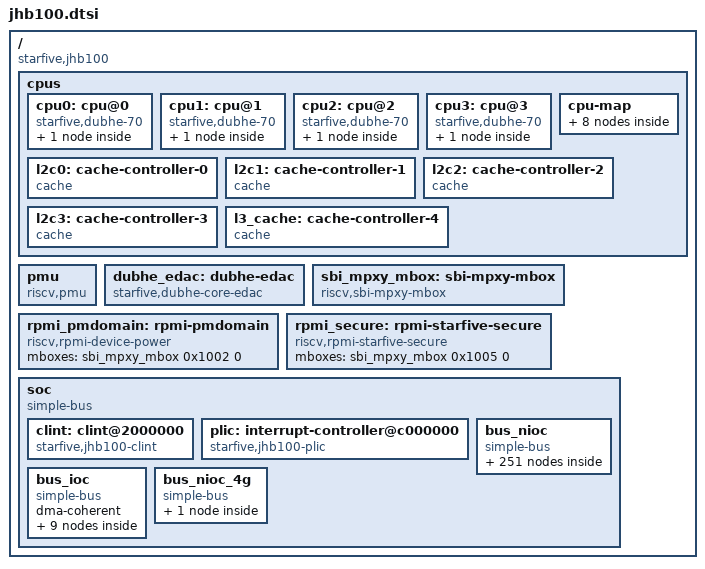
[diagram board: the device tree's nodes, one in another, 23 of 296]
// SPDX-License-Identifier: GPL-2.0 OR MIT
/*
 * Copyright (c) 2024 StarFive Technology Co., Ltd.
 */

/dts-v1/;
#include <dt-bindings/power/starfive,jhb100-power.h>
#include <dt-bindings/gpio/starfive,jhb100-gpio.h>
#include <dt-bindings/gpio/gpio.h>
#include "jhb100-crg.dtsi"
#include "jhb100-pinfunc.h"

/ {
	compatible = "starfive,jhb100";
	#address-cells = <2>;
	#size-cells = <2>;

	cpus {
		#address-cells = <1>;
		#size-cells = <0>;

		cpu0: cpu@0 {
			compatible = "starfive,dubhe-70", "riscv";
			riscv,isa = "rv64imafdcbh";
			riscv,isa-base = "rv64i";
			riscv,isa-extensions = "i", "m", "a", "f", "d", "c", "h", "zba", "zbb",
					       "zbc", "zbs", "zicbom", "zicbop", "zicboz", "zicntr",
					       "zicond", "zicsr", "zifencei", "zihintpause",
					       "zihpm", "svinval", "svnapot", "sscofpmf";
			riscv,cbom-block-size = <64>;
			riscv,cboz-block-size = <64>;
			d-cache-block-size = <64>;
			d-cache-sets = <512>;
			d-cache-size = <32768>;
			d-tlb-sets = <1>;
			d-tlb-size = <16>;
			device_type = "cpu";
			i-cache-block-size = <64>;
			i-cache-sets = <512>;
			i-cache-size = <32768>;
			i-tlb-sets = <1>;
			i-tlb-size = <24>;
			mmu-type = "riscv,sv48";
			next-level-cache = <&l2c0>;
			reg = <0x0>;
			tlb-split;

			cpu0_intc: interrupt-controller {
				compatible = "riscv,cpu-intc";
				interrupt-controller;
				#interrupt-cells = <1>;
			};
		};

		cpu1: cpu@1 {
			compatible = "starfive,dubhe-70", "riscv";
			riscv,isa = "rv64imafdcbh";
			riscv,isa-base = "rv64i";
			riscv,isa-extensions = "i", "m", "a", "f", "d", "c", "h", "zba", "zbb",
					       "zbc", "zbs", "zicbom", "zicbop", "zicboz", "zicntr",
					       "zicond", "zicsr", "zifencei", "zihintpause",
					       "zihpm", "svinval", "svnapot", "sscofpmf";
			riscv,cbom-block-size = <64>;
			riscv,cboz-block-size = <64>;
			d-cache-block-size = <64>;
			d-cache-sets = <512>;
			d-cache-size = <32768>;
			d-tlb-sets = <1>;
			d-tlb-size = <16>;
			device_type = "cpu";
			i-cache-block-size = <64>;
			i-cache-sets = <512>;
			i-cache-size = <32768>;
			i-tlb-sets = <1>;
			i-tlb-size = <24>;
			mmu-type = "riscv,sv48";
			next-level-cache = <&l2c1>;
			reg = <0x1>;
			tlb-split;

			cpu1_intc: interrupt-controller {
				compatible = "riscv,cpu-intc";
				interrupt-controller;
				#interrupt-cells = <1>;
			};
		};

		cpu2: cpu@2 {
			compatible = "starfive,dubhe-70", "riscv";
			riscv,isa = "rv64imafdcbh";
			riscv,isa-base = "rv64i";
			riscv,isa-extensions = "i", "m", "a", "f", "d", "c", "h", "zba", "zbb",
					       "zbc", "zbs", "zicbom", "zicbop", "zicboz", "zicntr",
					       "zicond", "zicsr", "zifencei", "zihintpause",
					       "zihpm", "svinval", "svnapot", "sscofpmf";
			riscv,cbom-block-size = <64>;
			riscv,cboz-block-size = <64>;
			d-cache-block-size = <64>;
			d-cache-sets = <512>;
			d-cache-size = <32768>;
			d-tlb-sets = <1>;
			d-tlb-size = <16>;
			device_type = "cpu";
			i-cache-block-size = <64>;
			i-cache-sets = <512>;
			i-cache-size = <32768>;
			i-tlb-sets = <1>;
			i-tlb-size = <24>;
			mmu-type = "riscv,sv48";
			next-level-cache = <&l2c2>;
			reg = <0x2>;
			tlb-split;

			cpu2_intc: interrupt-controller {
				compatible = "riscv,cpu-intc";
				interrupt-controller;
				#interrupt-cells = <1>;
			};
		};

		cpu3: cpu@3 {
			compatible = "starfive,dubhe-70", "riscv";
			riscv,isa = "rv64imafdcbh";
			riscv,isa-base = "rv64i";
			riscv,isa-extensions = "i", "m", "a", "f", "d", "c", "h", "zba", "zbb",
					       "zbc", "zbs", "zicbom", "zicbop", "zicboz", "zicntr",
					       "zicond", "zicsr", "zifencei", "zihintpause",
					       "zihpm", "svinval", "svnapot", "sscofpmf";
			riscv,cbom-block-size = <64>;
			riscv,cboz-block-size = <64>;
			d-cache-block-size = <64>;
			d-cache-sets = <512>;
			d-cache-size = <32768>;
			d-tlb-sets = <1>;
			d-tlb-size = <16>;
			device_type = "cpu";
			i-cache-block-size = <64>;
			i-cache-sets = <512>;
			i-cache-size = <32768>;
			i-tlb-sets = <1>;
			i-tlb-size = <24>;
			mmu-type = "riscv,sv48";
			next-level-cache = <&l2c3>;
			reg = <0x3>;
			tlb-split;

			cpu3_intc: interrupt-controller {
				compatible = "riscv,cpu-intc";
				interrupt-controller;
				#interrupt-cells = <1>;
			};
		};

		cpu-map {
			cluster0 {
				core0 {
					cpu = <&cpu0>;
				};
			};

			cluster1 {
				core0 {
					cpu = <&cpu1>;
				};
			};

			cluster2 {
				core0 {
					cpu = <&cpu2>;
				};
			};

			cluster3 {
				core0 {
					cpu = <&cpu3>;
				};
			};
		};

		l2c0: cache-controller-0 {
			compatible = "cache";
			cache-block-size = <64>;
			cache-level = <2>;
			cache-sets = <2048>;
			cache-size = <0x20000>;
			cache-unified;
			next-level-cache = <&l3_cache>;
		};

		l2c1: cache-controller-1 {
			compatible = "cache";
			cache-block-size = <64>;
			cache-level = <2>;
			cache-sets = <2048>;
			cache-size = <0x20000>;
			cache-unified;
			next-level-cache = <&l3_cache>;
		};

		l2c2: cache-controller-2 {
			compatible = "cache";
			cache-block-size = <64>;
			cache-level = <2>;
			cache-sets = <2048>;
			cache-size = <0x20000>;
			cache-unified;
			next-level-cache = <&l3_cache>;
		};

		l2c3: cache-controller-3 {
			compatible = "cache";
			cache-block-size = <64>;
			cache-level = <2>;
			cache-sets = <2048>;
			cache-size = <0x20000>;
			cache-unified;
			next-level-cache = <&l3_cache>;
		};

		l3_cache: cache-controller-4 {
			compatible = "cache";
			cache-block-size = <64>;
			cache-level = <3>;
			cache-sets = <1024>;
			cache-size = <0x20000>;
			cache-unified;
		};
	};

	pmu {
		compatible = "riscv,pmu";
		interrupts-extended = <&cpu0_intc 13>, <&cpu1_intc 13>,
				      <&cpu2_intc 13>, <&cpu3_intc 13>;

		riscv,event-to-mhpmevent = <0x00005 0x0000 0xA>,
					   <0x00006 0x0000 0xB>,
					   <0x00008 0x0000 0x10>,
					   <0x00009 0x0000 0xF>,
					   <0x10000 0x0000 0x19>,
					   <0x10001 0x0000 0x1A>,
					   <0x10002 0x0000 0x1B>,
					   <0x10003 0x0000 0x1C>,
					   <0x10008 0x0000 0x8>,
					   <0x10009 0x0000 0x9>,
					   <0x1000C 0x0000 0x9E>,
					   <0x1000D 0x0000 0x9F>,
					   <0x10010 0x0000 0x1D>,
					   <0x10011 0x0000 0x1E>,
					   <0x10012 0x0000 0x1F>,
					   <0x10013 0x0000 0x20>,
					   <0x10014 0x0000 0x21>,
					   <0x10018 0x0000 0x17>,
					   <0x10019 0x0000 0x18>,
					   <0x10020 0x0000 0x8>,
					   <0x10021 0x0000 0x7>;

		riscv,event-to-mhpmcounters = <0x00005 0x00006 0x00007FF8>,
					      <0x00008 0x00009 0x00007FF8>,
					      <0x10000 0x10003 0x00007FF8>,
					      <0x10008 0x10009 0x00007FF8>,
					      <0x1000C 0x1000D 0x00007FF8>,
					      <0x10010 0x10014 0x00007FF8>,
					      <0x10018 0x10019 0x00007FF8>,
					      <0x10020 0x10021 0x00007FF8>;

		riscv,raw-event-to-mhpmcounters =
			<0x00 0x00 0xFFFFFFFF 0xFFFFFFE0 0x00007FF8>,	/* Event ID 1-31 */
			<0x00 0x20 0xFFFFFFFF 0xFFFFFFFE 0x00007FF8>,	/* Event ID 32-33 */
			<0x00 0x22 0xFFFFFFFF 0xFFFFFF22 0x00007FF8>;	/* Event ID 34 */
	};

	dubhe_edac: dubhe-edac {
		compatible = "starfive,dubhe-core-edac";
	};

	sbi_mpxy_mbox: sbi-mpxy-mbox {
		compatible = "riscv,sbi-mpxy-mbox";
		#mbox-cells = <0x02>;
	};

	rpmi_pmdomain: rpmi-pmdomain {
		compatible = "riscv,rpmi-device-power";
		mboxes = <&sbi_mpxy_mbox 0x1002 0>;
		#power-domain-cells = <1>;
	};

	rpmi_secure: rpmi-starfive-secure {
		compatible = "riscv,rpmi-starfive-secure";
		mboxes = <&sbi_mpxy_mbox 0x1005 0>;
	};

	soc {
		compatible = "simple-bus";
		interrupt-parent = <&plic>;
		#address-cells = <2>;
		#size-cells = <2>;
		dma-ranges;
		ranges;

		clint: clint@2000000 {
			compatible = "starfive,jhb100-clint", "sifive,clint0";
			reg = <0x0 0x02000000 0x0 0x10000>;
			interrupts-extended = <&cpu0_intc 3>, <&cpu0_intc 7>,
					      <&cpu1_intc 3>, <&cpu1_intc 7>,
					      <&cpu2_intc 3>, <&cpu2_intc 7>,
					      <&cpu3_intc 3>, <&cpu3_intc 7>;
		};

		plic: interrupt-controller@c000000 {
			#interrupt-cells = <1>;
			compatible = "starfive,jhb100-plic", "sifive,plic-1.0.0";
			reg = <0x0 0x0c000000 0x0 0x4000000>;
			riscv,ndev = <400>;
			interrupt-controller;
			interrupts-extended = <&cpu0_intc 11>, <&cpu0_intc 9>,
					      <&cpu1_intc 11>, <&cpu1_intc 9>,
					      <&cpu2_intc 11>, <&cpu2_intc 9>,
					      <&cpu3_intc 11>, <&cpu3_intc 9>;
		};

		bus_nioc: bus_nioc {
			compatible = "simple-bus";
			#address-cells = <2>;
			#size-cells = <2>;
			dma-noncoherent;
			dma-ranges = <0x4 0x00000000 0x0 0x40000000 0x2 0x0>,
				     <0x4 0x00000000 0x4 0x00000000 0x2 0x0>;
			ranges;

			pcie_ep0: pcie-ep@10000000 {
				compatible = "starfive,jhb100-pcie-ep";
				reg = <0x0 0x10000000 0x0 0x100000>,
				<0x0 0x10100000 0x0 0x100000>,
				<0x0 0x10300000 0x0 0x1ff24>,
				<0x0 0x10380000 0x0 0x10000>,
				<0x0 0x10680000 0x0 0x8000>,
				<0x0 0x11120000 0x0 0x8000>,
				<0x0 0x11135000 0x0 0x1000>,
				<0x0 0x20000000 0x0 0x4000000>;
				reg-names = "dbi", "dbi2", "atu", "hdma", "usb", "dc", "vout",
					"addr_space";
				interrupts-extended = <&intc 53>, <&intc 54>,
					<&plic 264>, <&plic 265>, <&plic 267>, <&plic 269>;
				interrupt-names = "perst_pe", "perst_ne", "pm_link", "flr",
					"err", "h2b";
				clocks = <&host0crg JHB100_HOST0CLK_MAIN_ICG_EN_PCIE0_EP>,
					<&host0crg JHB100_HOST0CLK_PCIE0_EP_MSTR_ACLK>,
					<&host0crg JHB100_HOST0CLK_PCIE0_EP_SLV_ACLK>,
					<&host0crg JHB100_HOST0CLK_PCIE0_EP_DBI_ACLK>,
					<&host0crg JHB100_HOST0CLK_MAIN_ICG_EN_PCIE0_ECSR>,
					<&host0crg JHB100_HOST0CLK_PCIE0_EP_PHY_APB_CLK>;
				resets = <&host0crg JHB100_HOST0RST_PCIE0_EP_SW_CORE_RST_N>,
					<&host0crg JHB100_HOST0RST_MAIN_RSTN_DW_PCIE0_EP>,
					<&host0crg JHB100_HOST0RST_PCIE0_EP_SW_PHY_RST_N>,
					<&host0crg JHB100_HOST0RST_PCIE0_EP_SW_PHY_PERST_N>,
					<&host0crg JHB100_HOST0RST_MAIN_RSTN_PCIEEP0_ECSR>,
					<&host0crg JHB100_HOST0RST_PCIE0_EP_PERST_N>,
					<&host0crg JHB100_HOST0RST_PCIE0_EP_PHY_APB_RST_N>;
				reset-names = "core", "main", "phy", "phy_pe", "ecsr",
					"dw_pe", "apb";
				max-functions = <7>;
				max-link-speed = <4>;
				num-lanes = <1>;
				ecsr-syscon = <&pcie_ep0_ecsr>;
				starfive,ep-id = <0>;
				starfive,syscon = <&sys_syscon 48 4>;
				status = "disabled";
			};

			pcie0_mctp: mctp@10510000 {
				compatible = "starfive,jhb100-mctp";
				reg = <0x0 0x10510000 0x0 0x1000>;
				interrupts-extended = <&plic 299>, <&plic 300>, <&plic 301>,
					<&plic 302>, <&plic 303>, <&plic 304>, <&plic 305>,
					<&plic 306>, <&intc 53>, <&intc 54>;
				interrupt-names = "tx_cmpl", "rx_cmpl", "rx_rdy", "tx_vdm_full",
					"rx_vdm_full", "rx_cmd_full", "tx_err", "rx_err",
					"pcie_deassert", "pcie_assert";
				clocks = <&host0crg JHB100_HOST0CLK_MAIN_ICG_EN_MCTP0_EP>,
					<&host0crg JHB100_HOST0CLK_PCIE0_MCTP_ACLK_M>,
					<&host0crg JHB100_HOST0CLK_PCIE0_MCTP_ACLK_S>,
					<&host0crg JHB100_HOST0CLK_PCIE0_MCTP_PCLK>;
				resets = <&host0crg JHB100_HOST0RST_MAIN_RSTN_MCTP0_EP>;
				starfive,pcie-ecsr = <&pcie_ep0_ecsr>;
				starfive,rx-cmd-full-th = <60>;
				starfive,rx-cmd-empty-th = <0>;
				starfive,rx-ring-count = <64>;
				starfive,syscon = <&sys_syscon 48 4>;
				starfive,tx-cmd-full-th = <15>;
				starfive,tx-cmd-empty-th = <0>;
				starfive,tx-ring-count = <64>;
				status = "disabled";
			};

			pcie_ep0_ecsr: syscon@10511000 {
				compatible = "starfive,jhb100-pcie-ecsr-syscon", "syscon";
				reg = <0x0 0x10511000 0x0 0x1000>;
			};

			pcie0_mmbi: mmbi@10512000 {
				compatible = "starfive,jhb100-mmbi-pcie";
				reg = <0x0 0x10512000 0x0 0x800>;
				interrupts-extended = <&plic 289>, <&plic 290>, <&plic 291>, <&plic 292>,
						      <&plic 293>, <&plic 294>, <&plic 295>, <&plic 296>,
						      <&intc 53>, <&intc 57>;
				clocks = <&host0crg JHB100_HOST0CLK_MAIN_ICG_EN_MMBI_PCIE0>;
				resets = <&host0crg JHB100_HOST0RST_MAIN_RSTN_MMBI_PCIE0>;
				mmbi-id = <0>;
				status = "disabled";
			};

			espi0_mmbi: mmbi@10580000 {
				compatible = "starfive,jhb100-mmbi-espi";
				reg = <0x0 0x10580000 0x0 0x800>;
				interrupts-extended = <&plic 272>, <&plic 273>, <&plic 274>, <&plic 275>,
						      <&plic 276>, <&plic 277>, <&plic 278>, <&plic 279>,
						      <&intc 57>;
				clocks = <&host0crg JHB100_HOST0CLK_MAIN_ICG_EN_MMBI_ESPI0>;
				resets = <&host0crg JHB100_HOST0RST_MAIN_RSTN_MMBI_ESPI0>;
				mmbi-id = <0>;
				status = "disabled";
			};

			sio0: superio@10582000 {
				compatible = "starfive,jhb100-sio", "simple-mfd", "syscon";
				reg = <0x0 0x10582000 0x0 0x1000>;
				#address-cells = <2>;
				#size-cells = <2>;
				starfive,sio-id = <0>;
				status = "disabled";
				ranges = <0x0 0x0 0x0 0x10582000 0x0 0x1000>;

				sio0_bt0: bt@0 {
					compatible = "starfive,jhb100-bt-bmc";
					reg = <0x0 0x0 0x0 0x100>;
					interrupts-extended = <&plic 280>, <&intc 57>;
					interrupt-names = "bt", "espi_rst";
					status = "disabled";
				};

				sio0_bt1: bt@100 {
					compatible = "starfive,jhb100-bt-bmc";
					reg = <0x0 0x100 0x0 0x100>;
					interrupts-extended = <&plic 281>, <&intc 57>;
					interrupt-names = "bt", "espi_rst";
					status = "disabled";
				};

				sio0_kcs0: kcs@200 {
					compatible = "starfive,jhb100-kcs-bmc";
					reg = <0x0 0x200 0x0 0x100>;
					interrupts-extended = <&plic 282>, <&intc 57>;
					interrupt-names = "kcs", "espi_rst";
					status = "disabled";
				};

				sio0_kcs1: kcs@300 {
					compatible = "starfive,jhb100-kcs-bmc";
					reg = <0x0 0x300 0x0 0x100>;
					interrupts-extended = <&plic 283>, <&intc 57>;
					interrupt-names = "kcs", "espi_rst";
					status = "disabled";
				};

				sio0_kcs2: kcs@400 {
					compatible = "starfive,jhb100-kcs-bmc";
					reg = <0x0 0x400 0x0 0x100>;
					interrupts-extended = <&plic 284>, <&intc 57>;
					interrupt-names = "kcs", "espi_rst";
					status = "disabled";
				};

				sio0_kcs3: kcs@500 {
					compatible = "starfive,jhb100-kcs-bmc";
					reg = <0x0 0x500 0x0 0x100>;
					interrupts-extended = <&plic 285>, <&intc 57>;
					interrupt-names = "kcs", "espi_rst";
					status = "disabled";
				};

				sio0_mbox: mbox@600 {
					compatible = "starfive,jhb100-sio-mbox";
					reg = <0x0 0x600 0x0 0x100>;
					interrupts-extended = <&plic 286>, <&intc 57>;
					interrupt-names = "mbox", "espi_rst";
					status = "disabled";
				};

				sio0_pcc: pcc@800 {
					compatible = "starfive,jhb100-sio-pcc";
					reg = <0x0 0x800 0x0 0x100>;
					interrupts-extended = <&plic 287>, <&intc 57>;
					interrupt-names = "pcc", "espi_rst";
					status = "disabled";
				};

				sio0_wdi: wdi@900 {
					compatible = "starfive,jhb100-sio-wdi";
					reg = <0x0 0x900 0x0 0x100>;
					interrupts-extended = <&plic 288>, <&intc 57>;
					interrupt-names = "wdi", "espi_rst";
					status = "disabled";
				};
			};

			espi0: espi-slave@10584000 {
				compatible = "starfive,jhb100-espi-slave";
				reg = <0x0 0x10584000 0x0 0x2000>;
				starfive,espi-id = <0>;
				espi-dma-mode = <0x01>;
				starfive,vw-hw-enable;
				espi-wait-state = <4>;
				perif-memcyc-enable;
				flash-safs-mode = <1>;
				interrupts = <297>, <298>;
				interrupt-names = "espi", "safs";
				clocks = <&host0crg JHB100_HOST0CLK_MAIN_ICG_EN_ESPI0_EDAF>,
					 <&host0crg JHB100_HOST0CLK_MAIN_ICG_EN_SUPERIO0>;
				resets = <&host0crg JHB100_HOST0RST_MAIN_RSTN_ESPI0_SLAVE_POK>,
					 <&host0crg JHB100_HOST0RST_MAIN_RSTN_SUPERIO0_ESPI>;
				reset-names = "espi", "sio";
				starfive,syscon = <&sys_syscon 52>;

				status = "disabled";
			};

			sol0: sol@105c0800 {
				compatible = "starfive,jhb100-sol";
				reg = <0x0 0x105c0800 0x0 0x400>;
				interrupt-parent = <&intc>;
				interrupts = <5>;
				clocks = <&host0crg JHB100_HOST0CLK_MAIN_ICG_EN_SOL0>;
				resets = <&host0crg JHB100_HOST0RST_MAIN_RSTN_SOL0>;
				status = "disabled";
			};

			sol1: sol@105c0c00 {
				compatible = "starfive,jhb100-sol";
				reg = <0x0 0x105c0c00 0x0 0x400>;
				interrupt-parent = <&intc>;
				interrupts = <6>;
				clocks = <&host0crg JHB100_HOST0CLK_MAIN_ICG_EN_SOL1>;
				resets = <&host0crg JHB100_HOST0RST_MAIN_RSTN_SOL1>;
				status = "disabled";
			};

			husb0d0: usb@10600000 {
				compatible = "starfive,jhb100-dwc3-device";
				#address-cells = <2>;
				#size-cells = <2>;
				clocks = <&husbd0crg JHB100_HUSBD0CLK_MAIN_ICG_EN_USB3_DEV0>;
				resets = <&husbd0crg JHB100_HUSBD0RST_USB3_DEV0_WRAP_VCC>;
				starfive,syscon = <&husbd0syscon 0>;
				ranges;
				status = "disabled";

				husb0dcore0: usb@10600000 {
					compatible = "snps,dwc3";
					reg = <0x0 0x10600000 0x0 0x10000>;
					interrupts = <245>;
					clocks = <&husbd0crg JHB100_HUSBD0CLK_USB3_DEV0_BUSCLK>,
						<&husbd0crg JHB100_HUSBD0CLK_USB3_DEV0_SUSPENDCLK>;
					clock-names = "bus_early", "suspend";
					maximum-speed = "super-speed";
					snps,usb2-gadget-lpm-disable;
					dr_mode = "peripheral";
				};
			};

			husb0d1: usb@10610000 {
				compatible = "starfive,jhb100-dwc3-device";
				#address-cells = <2>;
				#size-cells = <2>;
				clocks = <&husbd0crg JHB100_HUSBD0CLK_MAIN_ICG_EN_USB3_DEV1>;
				resets = <&husbd0crg JHB100_HUSBD0RST_USB3_DEV1_WRAP_VCC>;
				starfive,syscon = <&husbd0syscon 1>;
				ranges;
				status = "disabled";

				husb0dcore1: usb@10610000 {
					compatible = "snps,dwc3";
					reg = <0x0 0x10610000 0x0 0x10000>;
					interrupts = <246>;
					clocks = <&husbd0crg JHB100_HUSBD0CLK_USB3_DEV1_BUSCLK>,
						<&husbd0crg JHB100_HUSBD0CLK_USB3_DEV1_SUSPENDCLK>;
					clock-names = "bus_early", "suspend";
					maximum-speed = "super-speed";
					snps,usb2-gadget-lpm-disable;
					dr_mode = "peripheral";
				};
			};

			husb0d2: usb@10620000 {
				compatible = "starfive,jhb100-dwc3-device";
				#address-cells = <2>;
				#size-cells = <2>;
				clocks = <&husbd0crg JHB100_HUSBD0CLK_MAIN_ICG_EN_USB3_DEV2>;
				resets = <&husbd0crg JHB100_HUSBD0RST_USB3_DEV2_WRAP_VCC>;
				starfive,syscon = <&husbd0syscon 2>;
				ranges;
				status = "disabled";

				husb0dcore2: usb@10620000 {
					compatible = "snps,dwc3";
					reg = <0x0 0x10620000 0x0 0x10000>;
					clocks = <&husbd0crg JHB100_HUSBD0CLK_USB3_DEV2_BUSCLK>,
						<&husbd0crg JHB100_HUSBD0CLK_USB3_DEV2_SUSPENDCLK>;
					clock-names = "bus_early", "suspend";
					interrupts = <247>;
					maximum-speed = "super-speed";
					snps,usb2-gadget-lpm-disable;
					dr_mode = "peripheral";
				};
			};

			husb0d3: usb@10630000 {
				compatible = "starfive,jhb100-dwc3-device";
				#address-cells = <2>;
				#size-cells = <2>;
				clocks = <&husbd0crg JHB100_HUSBD0CLK_MAIN_ICG_EN_USB3_DEV3>;
				resets = <&husbd0crg JHB100_HUSBD0RST_USB3_DEV3_WRAP_VCC>;
				starfive,syscon = <&husbd0syscon 3>;
				ranges;
				status = "disabled";

				husb0dcore3: usb@10630000 {
					compatible = "snps,dwc3";
					reg = <0x0 0x10630000 0x0 0x10000>;
					clocks = <&husbd0crg JHB100_HUSBD0CLK_USB3_DEV3_BUSCLK>,
						<&husbd0crg JHB100_HUSBD0CLK_USB3_DEV3_SUSPENDCLK>;
					clock-names = "bus_early", "suspend";
					maximum-speed = "super-speed";
					interrupts = <248>;
					snps,usb2-gadget-lpm-disable;
					dr_mode = "peripheral";
				};
			};

			husb0d4: usb@10640000 {
				compatible = "starfive,jhb100-dwc3-device";
				#address-cells = <2>;
				#size-cells = <2>;
				clocks = <&husbd0crg JHB100_HUSBD0CLK_MAIN_ICG_EN_USB3_DEV4>;
				resets = <&husbd0crg JHB100_HUSBD0RST_USB3_DEV4_WRAP_VCC>;
				starfive,syscon = <&husbd0syscon 4>;
				ranges;
				status = "disabled";

				husb0dcore4: usb@10640000 {
					compatible = "snps,dwc3";
					reg = <0x0 0x10640000 0x0 0x10000>;
					clocks = <&husbd0crg JHB100_HUSBD0CLK_USB3_DEV4_BUSCLK>,
						<&husbd0crg JHB100_HUSBD0CLK_USB3_DEV4_SUSPENDCLK>;
					clock-names = "bus_early", "suspend";
					maximum-speed = "super-speed";
					interrupts = <249>;
					snps,usb2-gadget-lpm-disable;
					dr_mode = "peripheral";
				};
			};

			husb0d5: usb@10650000 {
				compatible = "starfive,jhb100-dwc3-device";
				#address-cells = <2>;
				#size-cells = <2>;
				clocks = <&husbd0crg JHB100_HUSBD0CLK_MAIN_ICG_EN_USB3_DEV5>;
				resets = <&husbd0crg JHB100_HUSBD0RST_USB3_DEV5_WRAP_VCC>;
				starfive,syscon = <&husbd0syscon 5>;
				ranges;
				status = "disabled";

				husb0dcore5: usb@10650000 {
					compatible = "snps,dwc3";
					reg = <0x0 0x10650000 0x0 0x10000>;
					clocks = <&husbd0crg JHB100_HUSBD0CLK_USB3_DEV5_BUSCLK>,
						<&husbd0crg JHB100_HUSBD0CLK_USB3_DEV5_SUSPENDCLK>;
					clock-names = "bus_early", "suspend";
					interrupts = <250>;
					maximum-speed = "super-speed";
					snps,usb2-gadget-lpm-disable;
					dr_mode = "peripheral";
				};
			};

			husb0d6: usb@10660000 {
				compatible = "starfive,jhb100-dwc3-device";
				#address-cells = <2>;
				#size-cells = <2>;
				clocks = <&husbd0crg JHB100_HUSBD0CLK_MAIN_ICG_EN_USB2_DEV0>;
				resets = <&husbd0crg JHB100_HUSBD0RST_USB2_DEV0_WRAP_VCC>;
				starfive,syscon = <&husbd0syscon 6>;
				ranges;
				status = "disabled";

				husb0dcore6: usb@10660000 {
					compatible = "snps,dwc3";
					reg = <0x0 0x10660000 0x0 0x10000>;
					clocks = <&husbd0crg JHB100_HUSBD0CLK_USB2_DEV0_BUSCLK>;
					clock-names = "bus_early";
					interrupts = <243>;
					maximum-speed = "high-speed";
					snps,usb2-gadget-lpm-disable;
					dr_mode = "peripheral";
				};
			};

			husb0d7: usb@10670000 {
				compatible = "starfive,jhb100-dwc3-device";
				#address-cells = <2>;
				#size-cells = <2>;
				clocks = <&husbd0crg JHB100_HUSBD0CLK_MAIN_ICG_EN_USB2_DEV1>;
				resets = <&husbd0crg JHB100_HUSBD0RST_USB2_DEV1_WRAP_VCC>;
				starfive,syscon = <&husbd0syscon 7>;
				ranges;
				status = "disabled";

				husb0dcore7: usb@10670000 {
					compatible = "snps,dwc3";
					reg = <0x0 0x10670000 0x0 0x10000>;
					clocks = <&husbd0crg JHB100_HUSBD0CLK_USB2_DEV1_BUSCLK>;
					clock-name = "bus_early";
					interrupts = <244>;
					maximum-speed = "high-speed";
					snps,usb2-gadget-lpm-disable;
					dr_mode = "peripheral";
				};
			};

			husb0: usb@10680000 {
				compatible = "starfive,jhb100-dwc3-mphost";
				#address-cells = <2>;
				#size-cells = <2>;
				clocks = <&husb0crg JHB100_HUSB0CLK_MAIN_ICG_EN_XHCI>;
				resets = <&husb0crg JHB100_HUSB0RST_MAIN_RSTN_XHCI>;
				starfive,syscon = <&husb0syscon 0>;
				starfive,husbcmn-syscon = <&husbcmnsyscon 0>;
				starfive,pcie-ecsr = <&pcie_ep0_ecsr>;
				starfive,sys0cfg = <&sys_syscon 48 4>;
				interrupts-extended = <&plic 251>;
				interrupt-names = "err";
				status = "disabled";
				ranges;

				husb0core: usb@10680000 {
					compatible = "snps,dwc3";
					reg = <0x0 0x10680000 0x0 0x10000>;
					clocks = <&husb0crg JHB100_HUSB0CLK_XHCI_BUSCLK>,
						<&husb0crg JHB100_HUSB0CLK_XHCI_REFCLK>,
						<&husb0crg JHB100_HUSB0CLK_XHCI_SUSPENDCLK>;
					clock-names = "bus_early", "ref", "suspend";
					interrupts = <252>;
					dr_mode = "host";
					snps,dis_rxdet_inp3_quirk;
				};
			};

			husb0syscon: syscon@10695000 {
				compatible = "starfive,jhb100-husb-syscon", "syscon";
				reg = <0x0 0x10695000 0x0 0x800>;
			};

			husbd0syscon: syscon@10695800 {
				compatible = "starfive,jhb100-husbd-syscon", "syscon";
				reg = <0x0 0x10695800 0x0 0x800>;
			};

			pvt_gpu0: pvt@10740000 {
				compatible = "starfive,jhb100-pvt";
				reg = <0x0 0x10740000 0x0 0x80>,
				      <0x0 0x10740080 0x0 0x80>,
				      <0x0 0x10740100 0x0 0x80>;
				reg-names = "common", "ts", "pd";
				clocks = <&gpu0crg JHB100_GPU0CLK_MAIN_ICG_EN_GPU0_SENSORS>;
				resets = <&gpu0crg JHB100_GPU0RST_MAIN_RSTN_GPU0_SENSORS>;
				interrupts = <41>;
				label = "pvt_gpu0";
				moortec,ts-coeff-g = <61400>;
				moortec,ts-coeff-h = <253700>;
				#thermal-sensor-cells = <1>;
				status = "disabled";
			};

			pcie_ep1: pcie-ep@10800000 {
				compatible = "starfive,jhb100-pcie-ep";
				reg = <0x0 0x10800000 0x0 0x100000>,
				<0x0 0x10900000 0x0 0x100000>,
				<0x0 0x10b00000 0x0 0x1ff24>,
				<0x0 0x10b80000 0x0 0x10000>,
				<0x0 0x10680000 0x0 0x8000>,
				<0x0 0x11120000 0x0 0x8000>,
				<0x0 0x11135000 0x0 0x1000>,
				<0x0 0x24000000 0x0 0x4000000>;
				reg-names = "dbi", "dbi2", "atu", "hdma", "usb", "dc", "vout",
					"addr_space";
				interrupts-extended = <&intc 55>, <&intc 56>,
					<&plic 308>, <&plic 309>, <&plic 311>, <&plic 313>;
				interrupt-names = "perst_pe", "perst_ne", "pm_link", "flr",
					"err", "h2b";
				clocks = <&host1crg JHB100_HOST1CLK_MAIN_ICG_EN_PCIE1_EP>,
					<&host1crg JHB100_HOST1CLK_PCIE1_EP_MSTR_ACLK>,
					<&host1crg JHB100_HOST1CLK_PCIE1_EP_SLV_ACLK>,
					<&host1crg JHB100_HOST1CLK_PCIE1_EP_DBI_ACLK>,
					<&host1crg JHB100_HOST1CLK_MAIN_ICG_EN_PCIE1_ECSR>,
					<&host1crg JHB100_HOST1CLK_PCIE1_EP_PHY_APB_CLK>;
				resets = <&host1crg JHB100_HOST1RST_PCIE1_EP_SW_CORE_RST_N>,
					<&host1crg JHB100_HOST1RST_MAIN_RSTN_DW_PCIE1_EP>,
					<&host1crg JHB100_HOST1RST_PCIE1_EP_SW_PHY_RST_N>,
					<&host1crg JHB100_HOST1RST_PCIE1_EP_SW_PHY_PERST_N>,
					<&host1crg JHB100_HOST1RST_MAIN_RSTN_PCIEEP1_ECSR>,
					<&host1crg JHB100_HOST1RST_PCIE1_EP_PERST_N>,
					<&host1crg JHB100_HOST1RST_PCIE1_EP_PHY_APB_RST_N>;
				reset-names = "core", "main", "phy", "phy_pe", "ecsr",
					"dw_pe", "apb";
				max-functions = <7>;
				max-link-speed = <4>;
				num-lanes = <1>;
				ecsr-syscon = <&pcie_ep1_ecsr>;
				starfive,ep-id = <1>;
				starfive,syscon = <&sys_syscon 48 5>;
				status = "disabled";
			};

			pcie1_mctp: mctp@10d10000 {
				compatible = "starfive,jhb100-mctp";
				reg = <0x0 0x10d10000 0x0 0x1000>;
				interrupts-extended = <&plic 343>, <&plic 344>, <&plic 345>,
					<&plic 346>, <&plic 347>, <&plic 348>, <&plic 349>,
					<&plic 350>, <&intc 55>, <&intc 56>;
				interrupt-names = "tx_cmpl", "rx_cmpl", "rx_rdy", "tx_vdm_full",
					"rx_vdm_full", "rx_cmd_full", "tx_err", "rx_err",
					"pcie_deassert", "pcie_assert";
				clocks = <&host1crg JHB100_HOST1CLK_MAIN_ICG_EN_MCTP1_EP>,
					<&host1crg JHB100_HOST1CLK_PCIE1_MCTP_ACLK_M>,
					<&host1crg JHB100_HOST1CLK_PCIE1_MCTP_ACLK_S>,
					<&host1crg JHB100_HOST1CLK_PCIE1_MCTP_PCLK>;
				resets = <&host1crg JHB100_HOST1RST_MAIN_RSTN_MCTP1_EP>;
				starfive,pcie-ecsr = <&pcie_ep1_ecsr>;
				starfive,rx-cmd-full-th = <60>;
				starfive,rx-cmd-empty-th = <0>;
				starfive,rx-ring-count = <64>;
				starfive,syscon = <&sys_syscon 48 5>;
				starfive,tx-cmd-full-th = <15>;
				starfive,tx-cmd-empty-th = <0>;
				starfive,tx-ring-count = <64>;
				status = "disabled";
			};

			pcie_ep1_ecsr: syscon@10d11000 {
				compatible = "starfive,jhb100-pcie-ecsr-syscon", "syscon";
				reg = <0x0 0x10d11000 0x0 0x1000>;
			};

			pcie1_mmbi: mmbi@10d12000 {
				compatible = "starfive,jhb100-mmbi-pcie";
				reg = <0x0 0x10d12000 0x0 0x800>;
				interrupts-extended = <&plic 333>, <&plic 334>, <&plic 335>, <&plic 336>,
						      <&plic 337>, <&plic 338>, <&plic 339>, <&plic 340>,
						      <&intc 55>, <&intc 58>;
				clocks = <&host1crg JHB100_HOST1CLK_MAIN_ICG_EN_MMBI_PCIE1>;
				resets = <&host1crg JHB100_HOST1RST_MAIN_RSTN_MMBI_PCIE1>;
				mmbi-id = <1>;
				status = "disabled";
			};

			espi1_mmbi: mmbi@10d80000 {
				compatible = "starfive,jhb100-mmbi-espi";
				reg = <0x0 0x10d80000 0x0 0x800>;
				interrupts-extended = <&plic 316>, <&plic 316>, <&plic 318>, <&plic 319>,
						      <&plic 320>, <&plic 321>, <&plic 322>, <&plic 323>,
						      <&intc 58>;
				clocks = <&host1crg JHB100_HOST1CLK_MAIN_ICG_EN_MMBI_ESPI1>;
				resets = <&host1crg JHB100_HOST1RST_MAIN_RSTN_MMBI_ESPI1>;
				mmbi-id = <1>;
				status = "disabled";
			};

			sio1: superio@10d82000 {
				compatible = "starfive,jhb100-sio", "simple-mfd", "syscon";
				reg = <0x0 0x10d82000 0x0 0x1000>;
				#address-cells = <2>;
				#size-cells = <2>;
				starfive,sio-id = <1>;
				status = "disabled";
				ranges = <0x0 0x0 0x0 0x10d82000 0x0 0x1000>;

				sio1_bt0: bt@0 {
					compatible = "starfive,jhb100-bt-bmc";
					reg = <0x0 0x0 0x0 0x100>;
					interrupts-extended = <&plic 324>, <&intc 58>;
					interrupt-names = "bt", "espi_rst";
					status = "disabled";
				};

				sio1_bt1: bt@100 {
					compatible = "starfive,jhb100-bt-bmc";
					reg = <0x0 0x100 0x0 0x100>;
					interrupts-extended = <&plic 325>, <&intc 58>;
					interrupt-names = "bt", "espi_rst";
					status = "disabled";
				};

				sio1_kcs0: kcs@200 {
					compatible = "starfive,jhb100-kcs-bmc";
					reg = <0x0 0x200 0x0 0x100>;
					interrupts-extended = <&plic 326>, <&intc 58>;
					interrupt-names = "kcs", "espi_rst";
					status = "disabled";
				};

				sio1_kcs1: kcs@300 {
					compatible = "starfive,jhb100-kcs-bmc";
					reg = <0x0 0x300 0x0 0x100>;
					interrupts-extended = <&plic 327>, <&intc 58>;
					interrupt-names = "kcs", "espi_rst";
					status = "disabled";
				};

				sio1_kcs2: kcs@400 {
					compatible = "starfive,jhb100-kcs-bmc";
					reg = <0x0 0x400 0x0 0x100>;
					interrupts-extended = <&plic 328>, <&intc 58>;
					interrupt-names = "kcs", "espi_rst";
					status = "disabled";
				};

				sio1_kcs3: kcs@500 {
					compatible = "starfive,jhb100-kcs-bmc";
					reg = <0x0 0x500 0x0 0x100>;
					interrupts-extended = <&plic 329>, <&intc 58>;
					interrupt-names = "kcs", "espi_rst";
					status = "disabled";
				};

				sio1_mbox: mbox@600 {
					compatible = "starfive,jhb100-sio-mbox";
					reg = <0x0 0x600 0x0 0x100>;
					interrupts-extended = <&plic 330>, <&intc 58>;
					interrupt-names = "mbox", "espi_rst";
					status = "disabled";
				};

				sio1_pcc: pcc@800 {
					compatible = "starfive,jhb100-sio-pcc";
					reg = <0x0 0x800 0x0 0x100>;
					interrupts-extended = <&plic 331>, <&intc 58>;
					interrupt-names = "pcc", "espi_rst";
					status = "disabled";
				};

				sio1_wdi: wdi@900 {
					compatible = "starfive,jhb100-sio-wdi";
					reg = <0x0 0x900 0x0 0x100>;
					interrupts-extended = <&plic 332>, <&intc 58>;
					interrupt-names = "wdi", "espi_rst";
					status = "disabled";
				};
			};

			espi1: espi-slave@10d84000 {
				compatible = "starfive,jhb100-espi-slave";
				reg = <0x0 0x10d84000 0x0 0x2000>;
				starfive,espi-id = <1>;
				espi-dma-mode = <0x01>;
				starfive,vw-hw-enable;
				espi-wait-state = <4>;
				perif-memcyc-enable;
				flash-safs-mode = <1>;
				interrupts = <341>, <342>;
				interrupt-names = "espi", "safs";
				clocks = <&host1crg JHB100_HOST1CLK_MAIN_ICG_EN_ESPI1_EDAF>,
					 <&host1crg JHB100_HOST1CLK_MAIN_ICG_EN_SUPERIO1>;
				resets = <&host1crg JHB100_HOST1RST_MAIN_RSTN_ESPI1_SLAVE_POK>,
					 <&host1crg JHB100_HOST1RST_MAIN_RSTN_SUPERIO1_ESPI>;
				reset-names = "espi", "sio";
				starfive,syscon = <&sys_syscon 52>;

				status = "disabled";
			};

			sol2: sol@10dc0800 {
				compatible = "starfive,jhb100-sol";
				reg = <0x0 0x10dc0800 0x0 0x400>;
				interrupt-parent = <&intc>;
				interrupts = <7>;
				clocks = <&host1crg JHB100_HOST1CLK_MAIN_ICG_EN_SOL2>;
				resets = <&host1crg JHB100_HOST1RST_MAIN_RSTN_SOL2>;
				status = "disabled";
			};

			sol3: sol@10dc0c00 {
				compatible = "starfive,jhb100-sol";
				reg = <0x0 0x10dc0c00 0x0 0x400>;
				interrupt-parent = <&intc>;
				interrupts = <8>;
				clocks = <&host1crg JHB100_HOST1CLK_MAIN_ICG_EN_SOL3>;
				resets = <&host1crg JHB100_HOST1RST_MAIN_RSTN_SOL3>;
				status = "disabled";
			};

			husb1d0: usb@10e00000 {
				compatible = "starfive,jhb100-dwc3-device";
				#address-cells = <2>;
				#size-cells = <2>;
				clocks = <&husbd1crg JHB100_HUSBD1CLK_MAIN_ICG_EN_USB3_DEV0 >;
				resets = <&husbd1crg JHB100_HUSBD1RST_USB3_DEV0_WRAP_VCC>;
				starfive,syscon = <&husbd1syscon 0>;
				ranges;
				status = "disabled";

				husb1dcore0: usb@10e00000 {
					compatible = "snps,dwc3";
					reg = <0x0 0x10e00000 0x0 0x10000>;
					clocks = <&husbd1crg JHB100_HUSBD1CLK_USB3_DEV0_BUSCLK>,
						<&husbd1crg JHB100_HUSBD1CLK_USB3_DEV0_SUSPENDCLK>;
					clock-names = "bus_early", "suspend";
					interrupts = <255>;
					maximum-speed = "super-speed";
					snps,usb2-gadget-lpm-disable;
					dr_mode = "peripheral";
				};
			};

			husb1d1: usb@10e10000 {
				compatible = "starfive,jhb100-dwc3-device";
				#address-cells = <2>;
				#size-cells = <2>;
				clocks = <&husbd1crg JHB100_HUSBD1CLK_MAIN_ICG_EN_USB3_DEV1>;
				resets = <&husbd1crg JHB100_HUSBD1RST_USB3_DEV1_WRAP_VCC>;
				starfive,syscon = <&husbd1syscon 1>;
				ranges;
				status = "disabled";

				husb1dcore1: usb@10e10000 {
					compatible = "snps,dwc3";
					reg = <0x0 0x10e10000 0x0 0x10000>;
					clocks = <&husbd1crg JHB100_HUSBD1CLK_USB3_DEV1_BUSCLK>,
						<&husbd1crg JHB100_HUSBD1CLK_USB3_DEV1_SUSPENDCLK>;
					clock-names = "bus_early", "suspend";
					interrupts = <256>;
					maximum-speed = "super-speed";
					snps,usb2-gadget-lpm-disable;
					dr_mode = "peripheral";
				};
			};

			husb1d2: usb@10e20000 {
				compatible = "starfive,jhb100-dwc3-device";
				#address-cells = <2>;
				#size-cells = <2>;
				clocks = <&husbd1crg JHB100_HUSBD1CLK_MAIN_ICG_EN_USB3_DEV2>;
				resets = <&husbd1crg JHB100_HUSBD1RST_USB3_DEV2_WRAP_VCC>;
				starfive,syscon = <&husbd1syscon 2>;
				ranges;
				status = "disabled";

				husb1dcore2: usb@10e20000 {
					compatible = "snps,dwc3";
					reg = <0x0 0x10e20000 0x0 0x10000>;
					clocks = <&husbd1crg JHB100_HUSBD1CLK_USB3_DEV2_BUSCLK>,
						<&husbd1crg JHB100_HUSBD1CLK_USB3_DEV2_SUSPENDCLK>;
					clock-names = "bus_early", "suspend";
					interrupts = <257>;
					maximum-speed = "super-speed";
					snps,usb2-gadget-lpm-disable;
					dr_mode = "peripheral";
				};
			};

			husb1d3: usb@10e30000 {
				compatible = "starfive,jhb100-dwc3-device";
				#address-cells = <2>;
				#size-cells = <2>;
				clocks = <&husbd1crg JHB100_HUSBD1CLK_MAIN_ICG_EN_USB3_DEV3>;
				resets = <&husbd1crg JHB100_HUSBD1RST_USB3_DEV3_WRAP_VCC>;
				starfive,syscon = <&husbd1syscon 3>;
				ranges;
				status = "disabled";

				husb1dcore3: usb@10e30000 {
					compatible = "snps,dwc3";
					reg = <0x0 0x10e30000 0x0 0x10000>;
					clocks = <&husbd1crg JHB100_HUSBD1CLK_USB3_DEV3_BUSCLK>,
						<&husbd1crg JHB100_HUSBD1CLK_USB3_DEV3_SUSPENDCLK>;
					clock-names = "bus_early", "suspend";
					interrupts = <258>;
					maximum-speed = "super-speed";
					snps,usb2-gadget-lpm-disable;
					dr_mode = "peripheral";
				};
			};

			husb1d4: usb@10e40000 {
				compatible = "starfive,jhb100-dwc3-device";
				#address-cells = <2>;
				#size-cells = <2>;
				clocks = <&husbd1crg JHB100_HUSBD1CLK_MAIN_ICG_EN_USB3_DEV4>;
				resets = <&husbd1crg JHB100_HUSBD1RST_USB3_DEV4_WRAP_VCC>;
				starfive,syscon = <&husbd1syscon 4>;
				ranges;
				status = "disabled";

				husb1dcore4: usb@10e40000 {
					compatible = "snps,dwc3";
					reg = <0x0 0x10e40000 0x0 0x10000>;
					clocks = <&husbd1crg JHB100_HUSBD1CLK_USB3_DEV4_BUSCLK>,
						<&husbd1crg JHB100_HUSBD1CLK_USB3_DEV4_SUSPENDCLK>;
					clock-names = "bus_early", "suspend";
					interrupts = <259>;
					maximum-speed = "super-speed";
					snps,usb2-gadget-lpm-disable;
					dr_mode = "peripheral";
				};
			};

			husb1d5: usb@10e50000 {
				compatible = "starfive,jhb100-dwc3-device";
				#address-cells = <2>;
				#size-cells = <2>;
				clocks = <&husbd1crg JHB100_HUSBD1CLK_MAIN_ICG_EN_USB3_DEV5>;
				resets = <&husbd1crg JHB100_HUSBD1RST_USB3_DEV5_WRAP_VCC>;
				starfive,syscon = <&husbd1syscon 5>;
				ranges;
				status = "disabled";

				husb1dcore5: usb@10e50000 {
					compatible = "snps,dwc3";
					reg = <0x0 0x10e50000 0x0 0x10000>;
					clocks = <&husbd1crg JHB100_HUSBD1CLK_USB3_DEV5_BUSCLK>,
						<&husbd1crg JHB100_HUSBD1CLK_USB3_DEV5_SUSPENDCLK>;
					clock-names = "bus_early", "suspend";
					interrupts = <260>;
					maximum-speed = "super-speed";
					snps,usb2-gadget-lpm-disable;
					dr_mode = "peripheral";
				};
			};

			husb1d6: usb@10e60000 {
				compatible = "starfive,jhb100-dwc3-device";
				#address-cells = <2>;
				#size-cells = <2>;
				clocks = <&husbd1crg JHB100_HUSBD1CLK_MAIN_ICG_EN_USB2_DEV0>;
				resets = <&husbd1crg JHB100_HUSBD1RST_USB2_DEV0_WRAP_VCC>;
				starfive,syscon = <&husbd1syscon 6>;
				ranges;
				status = "disabled";

				husb1dcore6: usb@10e60000 {
					compatible = "snps,dwc3";
					reg = <0x0 0x10e60000 0x0 0x10000>;
					clocks = <&husbd1crg JHB100_HUSBD1CLK_USB2_DEV0_BUSCLK>;
					clock-names = "bus_early";
					interrupts = <253>;
					maximum-speed = "high-speed";
					snps,usb2-gadget-lpm-disable;
					dr_mode = "peripheral";
				};
			};

			husb1d7: usb@10e70000 {
				compatible = "starfive,jhb100-dwc3-device";
				#address-cells = <2>;
				#size-cells = <2>;
				clocks = <&husbd1crg JHB100_HUSBD1CLK_MAIN_ICG_EN_USB2_DEV1>;
				resets = <&husbd1crg JHB100_HUSBD1RST_USB2_DEV1_WRAP_VCC>;
				starfive,syscon = <&husbd1syscon 7>;
				ranges;
				status = "disabled";

				husb1dcore7: usb@10e70000 {
					compatible = "snps,dwc3";
					reg = <0x0 0x10e70000 0x0 0x10000>;
					clocks = <&husbd1crg JHB100_HUSBD1CLK_USB2_DEV1_BUSCLK>;
					clock-names = "bus_early";
					interrupts = <254>;
					maximum-speed = "high-speed";
					snps,usb2-gadget-lpm-disable;
					dr_mode = "peripheral";
				};
			};

			husb1: usb@10e80000 {
				compatible = "starfive,jhb100-dwc3-mphost";
				#address-cells = <2>;
				#size-cells = <2>;
				clocks = <&husb1crg JHB100_HUSB1CLK_MAIN_ICG_EN_XHCI>;
				resets = <&husb1crg JHB100_HUSB1RST_MAIN_RSTN_XHCI>;
				starfive,syscon = <&husb1syscon 0>;
				starfive,husbcmn-syscon = <&husbcmnsyscon 1>;
				starfive,pcie-ecsr = <&pcie_ep1_ecsr>;
				starfive,sys0cfg = <&sys_syscon 48 5>;
				interrupts-extended = <&plic 261>;
				interrupt-names = "err";
				ranges;
				status = "disabled";

				husb1core: usb@10e80000 {
					compatible = "snps,dwc3";
					reg = <0x0 0x10e80000 0x0 0x10000>;
					clocks = <&husb1crg JHB100_HUSB1CLK_XHCI_BUSCLK>,
						<&husb1crg JHB100_HUSB1CLK_XHCI_REFCLK>,
						<&husb1crg JHB100_HUSB1CLK_XHCI_SUSPENDCLK>;
					clock-names = "bus_early", "ref", "suspend";
					interrupts = <262>;
					dr_mode = "host";
					snps,dis_rxdet_inp3_quirk;
				};
			};

			husb1syscon: syscon@10e95000 {
				compatible = "starfive,jhb100-husb-syscon", "syscon";
				reg = <0x0 0x10e95000 0x0 0x800>;
			};

			husbd1syscon: syscon@10e95800 {
				compatible = "starfive,jhb100-husbd-syscon", "syscon";
				reg = <0x0 0x10e95800 0x0 0x800>;
			};

			pvt_gpu1: pvt@10f40000 {
				compatible = "starfive,jhb100-pvt";
				reg = <0x0 0x10f40000 0x0 0x80>,
				      <0x0 0x10f40080 0x0 0x80>,
				      <0x0 0x10f40100 0x0 0x80>;
				reg-names = "common", "ts", "pd";
				clocks = <&gpu1crg JHB100_GPU1CLK_MAIN_ICG_EN_GPU1_SENSORS>;
				resets = <&gpu1crg JHB100_GPU1RST_MAIN_RSTN_GPU1_SENSORS>;
				interrupts = <42>;
				label = "pvt_gpu1";
				moortec,ts-coeff-g = <61400>;
				moortec,ts-coeff-h = <253700>;
				#thermal-sensor-cells = <1>;
				status = "disabled";
			};

			husbphy0: phy@11000000 {
				compatible = "starfive,jhb100-phy-snps-femto-host";
				reg = <0x0 0x11000000 0x0 0x10000>;
				clocks = <&husbcmncrg JHB100_HUSBD0CLK_MAIN_ICG_EN_HUSB0>;
				resets = <&husbcmncrg JHB100_HUSBCMNRST_MAIN_RSTN_HOSTUSB0>,
					 <&husbd0crg JHB100_HUSBD0RST_HOST_SYSCON_RSTN>,
					 <&husbd0crg JHB100_HUSBD0RST_DEV_SYSCON_RSTN>;
				starfive,syscon = <&husbcmnsyscon 0>;
				#phy-cells = <1>;
				status = "disabled";
			};

			husbphy1: phy@11010000 {
				compatible = "starfive,jhb100-phy-snps-femto-host";
				reg = <0x0 0x11010000 0x0 0x10000>;
				clocks = <&husbcmncrg JHB100_HUSBD0CLK_MAIN_ICG_EN_HUSB1>;
				resets = <&husbcmncrg JHB100_HUSBCMNRST_MAIN_RSTN_HOSTUSB1>,
					 <&husbd1crg JHB100_HUSBD1RST_HOST_SYSCON_RSTN>,
					 <&husbd1crg JHB100_HUSBD1RST_DEV_SYSCON_RSTN>;
				starfive,syscon = <&husbcmnsyscon 1>;
				#phy-cells = <1>;
				status = "disabled";
			};

			pvt_usb: pvt@11040000 {
				compatible = "starfive,jhb100-pvt";
				reg = <0x0 0x11040000 0x0 0x80>,
				      <0x0 0x11040080 0x0 0x80>,
				      <0x0 0x11040100 0x0 0x80>;
				reg-names = "common", "ts", "pd";
				clocks = <&husbcmncrg JHB100_HUSBD0CLK_MAIN_ICG_EN_HUSBCMN_SENSOR>;
				resets = <&husbcmncrg JHB100_HUSBCMNRST_MAIN_RSTN_SENSOR_HOSTUSBCMN>;
				interrupts = <49>;
				label = "pvt_usb";
				moortec,ts-coeff-g = <61400>;
				moortec,ts-coeff-h = <253700>;
				#thermal-sensor-cells = <1>;
				status = "disabled";
			};

			husbcmnsyscon: syscon@11045000 {
				compatible = "starfive,jhb100-husbcmn-syscon", "syscon";
				reg = <0x0 0x11045000 0x0 0x1000>;
			};

			dp: dp@11100000 {
				compatible = "starfive,jhb100-dp";
				reg = <0x0 0x11100000 0x0 0x10000>,
				      <0x0 0x11135c00 0x0 0x100>;
				reg-names = "dp", "dynsw";
				resets = <&voutcrg JHB100_VOUTRST_MAIN_RSTN_DW_DPTX>,
					<&voutcrg JHB100_VOUTRST_MAIN_RSTN_U0_VOUT_DYNSW>;
				reset-names = "rstn_dp", "vout_dynsw0";
				interrupts = <228>, <237>, <238>, <232>;
				interrupt-names = "dp", "h2b0", "h2b1", "dynsw";
				b100,h2b-syscon = <&h2bsyscon>;
				b100,b2h-syscon = <&b2hsyscon>;
				dc-syscon = <&dcsyscon>;
				vout-syscon = <&voutsyscon>;
				status = "disabled";
			};

			voutsyscon: syscon@11134000 {
				compatible = "starfive,jhb100-vout-syscon", "syscon";
				reg = <0x0 0x11134000 0x0 0x1000>;
			};

			b2hsyscon: syscon@11135000 {
				compatible = "starfive,jhb100-b2h-syscon", "syscon";
				reg = <0x0 0x11135000 0x0 0x400>;
			};

			h2bsyscon: syscon@11135400 {
				compatible = "starfive,jhb100-h2b-syscon", "syscon";
				reg = <0x0 0x11135400 0x0 0x200>;
			};

			dcsyscon: syscon@11135800 {
				compatible = "starfive,jhb100-dc-syscon", "syscon";
				reg = <0x0 0x11135800 0x0 0x100>;
			};

			vga: vga@11136000 {
				compatible = "starfive,inno-vga";
				reg = <0x0 0x11136000 0x0 0x100>,
				      <0x0 0x11135d00 0x0 0x100>;
				interrupts-extended = <&plic 231>, <&plic 237>,
						      <&plic 238>, <&plic 233>,
						      <&pinctrl_bmcperiph0 28 GPIO_ACTIVE_HIGH>;
				interrupt-names = "vdac", "h02b", "h12b", "dynsw1", "switch";
				resets = <&voutcrg JHB100_VOUTRST_MAIN_RSTN_VGA>,
					 <&voutcrg JHB100_VOUTRST_MAIN_RSTN_VGA_SCAN>,
					 <&voutcrg JHB100_VOUTRST_MAIN_RSTN_U1_VOUT_DYNSW>;
				reset-names = "rstn_vga", "rstn_scan", "vout_dynsw1";
				h2b-syscon = <&h2bsyscon>;
				b2h-syscon = <&b2hsyscon>;
				dc-syscon = <&dcsyscon>;
				status = "disabled";
			};

			pinctrl_vga_vdac: vga_vdac@11136100 {
				compatible = "starfive,jhb100-pinctrl-vga-vdac";
				reg = <0x0 0x11136100 0x0 0x100>;
				resets = <&voutcrg JHB100_VOUTRST_MAIN_RSTN_VGA_IOMUX>;
				interrupts = <236>;
				interrupt-controller;
				#interrupt-cells = <2>;
				gpio-controller;
				#gpio-cells = <2>;
				gpio-ranges = <&pinctrl_vga_vdac 0 0 4>;
			};

			pvt_vce: pvt@11180000 {
				compatible = "starfive,jhb100-pvt";
				reg = <0x0 0x11180000 0x0 0x80>,
				      <0x0 0x11180080 0x0 0x80>,
				      <0x0 0x11180100 0x0 0x80>;
				reg-names = "common", "ts", "pd";
				clocks = <&vcecrg JHB100_VCECLK_MAIN_ICG_EN_VCE_SENSORS>;
				resets = <&vcecrg JHB100_VCERST_MAIN_RSTN_VCE_SENSORS>;
				interrupts = <46>;
				label = "pvt_vce";
				moortec,ts-coeff-g = <61400>;
				moortec,ts-coeff-h = <253700>;
				#thermal-sensor-cells = <1>;
				status = "disabled";
			};

			vce0: vce@11185000 {
				compatible = "starfive,jhb100-vce";
				reg = <0x0 0x11185000 0x0 0x800>,
					<0x0 0x11135e00 0x0 0x100>;
				reg-names = "vce", "dynsw";
				clocks = <&vcecrg JHB100_VCECLK_MAIN_ICG_EN_VCE0>;
				resets = <&vcecrg JHB100_VCERST_VCE0_TOP_ASYNC_RSTN>,
					<&voutcrg JHB100_VOUTRST_MAIN_RSTN_U2_VOUT_DYNSW>;
				reset-names = "rstn_vce", "vout_dynsw";
				interrupts = <240>, <237>, <234>;
				interrupt-names = "vce", "host2bmc", "dynsw";
				h2b-syscon = <&h2bsyscon>;
				vce-id = <0>;
				status = "disabled";
			};

			vce1: vce@11185800 {
				compatible = "starfive,jhb100-vce";
				reg = <0x0 0x11185800 0x0 0x800>,
					<0x0 0x11135f00 0x0 0x100>;
				reg-names = "vce", "dynsw";
				clocks = <&vcecrg JHB100_VCECLK_MAIN_ICG_EN_VCE1>;
				resets = <&vcecrg JHB100_VCERST_VCE1_TOP_ASYNC_RSTN>,
					<&voutcrg JHB100_VOUTRST_MAIN_RSTN_U3_VOUT_DYNSW>;
				reset-names = "rstn_vce", "vout_dynsw";
				interrupts = <241>, <238>, <235>;
				interrupt-names = "vce", "host2bmc", "dynsw";
				h2b-syscon = <&h2bsyscon>;
				vce-id = <1>;
				status = "disabled";
			};

			pcie_rc: pcie@11200000 {
				compatible = "starfive,jhb100-pcie-host";
				reg = <0x0 0x11200000 0x0 0x00400000>,
				      <0x0 0x28000000 0x0 0x00100000>;
				reg-names = "dbi", "config";
				device_type = "pci";
				#address-cells = <3>;
				#size-cells = <2>;
				ranges = <0x02000000 0x0 0x28100000 0x0 0x28100000 0x0 0x4000000>,
					 <0x43000000 0xc 0x00000000 0xc 0x00000000 0x1 0x00000000>;
				bus-range = <0x0 0xff>;
				clocks = <&pcierpcrg JHB100_PCIERPCLK_MAIN_ICG_EN_PCIERP_ECSR>,
					 <&pcierpcrg JHB100_PCIERPCLK_MAIN_ICG_EN_PCIERP>,
					 <&pcierpcrg JHB100_PCIERPCLK_MAIN_ICG_EN_MCTP>,
					 <&pcierpcrg JHB100_PCIERPCLK_MCTP_ACLK_M>,
					 <&pcierpcrg JHB100_PCIERPCLK_MCTP_ACLK_S>,
					 <&pcierpcrg JHB100_PCIERPCLK_MCTP_PCLK>;
				vendor-id = <0x20b5>;
				device-id = <0xb107>;
				interrupt-controller;
				interrupts = <86>, <87>, <88>, <90>;
				interrupt-names = "pm_link", "intx_msi", "err", "dma";
				#interrupt-cells = <1>;
				interrupt-map-mask = <0 0 0 7>;
				interrupt-map = <0 0 0 1 &pcie_rc 0>,
						<0 0 0 2 &pcie_rc 1>,
						<0 0 0 3 &pcie_rc 2>,
						<0 0 0 4 &pcie_rc 3>;
				max-link-speed = <2>;
				msi-controller;
				msi-parent = <&pcie_rc>;
				num-lanes = <1>;
				resets = <&pcierpcrg JHB100_PCIERPRST_MAIN_RSTN_PCIERP_ECSR>,
					<&pcierpcrg JHB100_PCIERPRST_MAIN_RSTN_DW_PCIE_RP>,
					<&pcierpcrg JHB100_PCIERPRST_MAIN_RSTN_MCTP_PCIERP>,
					<&pcierp_syscon_rst JHB100_PCIERP_SYSCONRST_PE2RST_OUT>;
				reset-names = "ecsr", "main", "mctp", "perst_out";
				ecsr-syscon = <&pcie_rp_ecsr>;

				status = "disabled";
			};

			pcierp_mctp: mctp@11710000 {
				compatible = "starfive,jhb100-mctp";
				reg = <0x0 0x11710000 0x0 0x1000>;
				interrupts-extended = <&plic 94>, <&plic 95>, <&plic 96>,
					<&plic 97>, <&plic 98>, <&plic 99>, <&plic 100>,
					<&plic 101>;
				interrupt-names = "tx_cmpl", "rx_cmpl", "rx_rdy", "tx_vdm_full",
					"rx_vdm_full", "rx_cmd_full", "tx_err", "rx_err";
				starfive,pcie-ecsr = <&pcie_rp_ecsr>;
				starfive,rx-cmd-full-th = <60>;
				starfive,rx-cmd-empty-th = <0>;
				starfive,rx-ring-count = <64>;
				starfive,tx-cmd-full-th = <15>;
				starfive,tx-cmd-empty-th = <0>;
				starfive,tx-ring-count = <64>;
				pcie_rc;
				status = "disabled";
			};

			pcie_rp_ecsr: syscon@11711000 {
				compatible = "starfive,jhb100-pcie-ecsr-syscon", "syscon";
				reg = <0x0 0x11711000 0x0 0x1000>;
			};

			usb0: usb@11800000 {
				compatible = "starfive,jhb100-dwc3-drd";
				#address-cells = <2>;
				#size-cells = <2>;
				clocks = <&usbcrg JHB100_USBCLK_MAIN_ICG_EN_BMCUSB_HOST>;
				resets = <&usbcrg JHB100_USBRST_MAIN_RSTN_HOST>;
				interrupts = <106>;
				interrupt-names = "err";
				starfive,syscon = <&usbsyscon 1>;
				status = "disabled";
				ranges;

				usb0core: usb@11800000 {
					compatible = "snps,dwc3";
					reg = <0x0 0x11800000 0x0 0x10000>;
					clocks = <&usbcrg JHB100_USBCLK_USB_HOST_USB3_BUS_CLK_EARLY>,
						<&usbcrg JHB100_USBCLK_USB_HOST_USB3_REF_CLK>;
					clock-names = "bus_early", "ref";
					interrupts = <107>;
				};
			};

			usb1: usb@11810000 {
				compatible = "starfive,jhb100-dwc3-drd";
				#address-cells = <2>;
				#size-cells = <2>;
				clocks = <&usbcrg JHB100_USBCLK_MAIN_ICG_EN_BMCUSB_DRD>;
				resets = <&usbcrg JHB100_USBRST_MAIN_RSTN_DRD>;
				interrupts = <104>;
				interrupt-names = "err";
				starfive,syscon = <&usbsyscon 0>;
				status = "disabled";
				ranges;

				usb1core: usb@11810000 {
					compatible = "snps,dwc3";
					reg = <0x0 0x11810000 0x0 0x10000>;
					clocks = <&usbcrg JHB100_USBCLK_USB_DRD_USB3_BUS_CLK_EARLY>,
						<&usbcrg JHB100_USBCLK_USB_DRD_USB3_REF_CLK>;
					clock-names = "bus_early", "ref";
					interrupts = <105>;
				};
			};

			usbsyscon: syscon@11820000 {
				compatible = "starfive,jhb100-usb-syscon", "syscon";
				reg = <0x0 0x11820000 0x0 0x2c>;
			};

			usbphy0: phy@1182002c {
				compatible = "starfive,jhb100-phy-snps-femto-usb2";
				reg = <0x0 0x1182002c 0x0 0xfd4>;
				#phy-cells = <1>;
				status = "disabled";
			};

			npu: vipni@11880000 {
				compatible = "starfive,vipni";
				reg = <0x0 0x11880000 0x0 0x40000>;
				interrupts = <77>;
				clocks = <&npucrg JHB100_NPUCLK_MAIN_ICG_EN_NPU>;
				resets = <&npucrg JHB100_NPURST_MAIN_RSTN_NPU>;
				power-domains = <&rpmi_pmdomain PD_NPU>;
				power-domain-names = "core_major";
				contiguous-base = <0x0>;
				contiguous-size = <0x1000000>;
				npu-syscon = <&npusyscon>;
				status = "disabled";
			};

			ltpi0: ltpi@11900000 {
				compatible = "starfive,ltpi";
				reg = <0x0 0x11900000 0x0 0x1000>;
				interrupts = <177>;
				clocks = <&per0crg JHB100_PER0CLK_240_CORE_LTPI0>,
					<&per0crg JHB100_PER0CLK_MAIN_ICG_EN_LTPI0>,
					<&per0crg JHB100_PER0CLK_PH0_LTPI0>,
					<&per0crg JHB100_PER0CLK_PH90_LTPI0>;
				clock-names = "core_clk", "apb", "lvds", "lvds90";
				resets = <&per0crg JHB100_PER0RST_MAIN_RSTN_LTPI0>;
				ltpi,id = <0>;
				status = "disabled";
			};

			llgpo0: virgpio@11901000 {
				compatible = "starfive,jhb100-virgpio";
				reg = <0x0 0x11901000 0x0 0x180>;
				clocks = <&per0crg JHB100_PER0CLK_MAIN_ICG_EN_LTPI0>;
				gpio-controller;
				#gpio-cells = <2>;
				direction = "output";
				ngpios = <64>;
				label = "llgpo0";
				status = "disabled";
			};

			llgpi0: virgpio@11901180 {
				compatible = "starfive,jhb100-virgpio";
				reg = <0x0 0x11901180 0x0 0x500>;
				clocks = <&per0crg JHB100_PER0CLK_MAIN_ICG_EN_LTPI0>;
				gpio-controller;
				#gpio-cells = <2>;
				interrupts = <178>;
				interrupt-controller;
				#interrupt-cells = <2>;
				direction = "input";
				ngpios = <64>;
				label = "llgpi0";
				status = "disabled";
			};

			nlgpo0: virgpio@11902000 {
				compatible = "starfive,jhb100-virgpio";
				reg = <0x0 0x11902000 0x0 0x180>;
				clocks = <&per0crg JHB100_PER0CLK_MAIN_ICG_EN_LTPI0>;
				gpio-controller;
				#gpio-cells = <2>;
				direction = "output";
				ngpios = <256>;
				label = "nlgpo0";
				status = "disabled";
			};

			nlgpi0: virgpio@11902180 {
				compatible = "starfive,jhb100-virgpio";
				reg = <0x0 0x11902180 0x0 0x500>;
				clocks = <&per0crg JHB100_PER0CLK_MAIN_ICG_EN_LTPI0>;
				gpio-controller;
				#gpio-cells = <2>;
				interrupts = <179>;
				interrupt-controller;
				#interrupt-cells = <2>;
				direction = "input";
				ngpios = <256>;
				label = "nlgpi0";
				status = "disabled";
			};

			ltpi1: ltpi@11910000 {
				compatible = "starfive,ltpi";
				reg = <0x0 0x11910000 0x0 0x1000>;
				interrupts = <180>;
				clocks = <&per0crg JHB100_PER0CLK_240_CORE_LTPI1>,
					<&per0crg JHB100_PER0CLK_MAIN_ICG_EN_LTPI1>,
					<&per0crg JHB100_PER0CLK_PH0_LTPI1>,
					<&per0crg JHB100_PER0CLK_PH90_LTPI1>;
				clock-names = "core_clk", "apb", "lvds", "lvds90";
				resets = <&per0crg JHB100_PER0RST_MAIN_RSTN_LTPI1>;
				ltpi,id = <1>;
				status = "disabled";
			};

			llgpo1: virgpio@11911000 {
				compatible = "starfive,jhb100-virgpio";
				reg = <0x0 0x11911000 0x0 0x180>;
				clocks = <&per0crg JHB100_PER0CLK_MAIN_ICG_EN_LTPI1>;
				gpio-controller;
				#gpio-cells = <2>;
				direction = "output";
				ngpios = <64>;
				label = "llgpo1";
				status = "disabled";
			};

			llgpi1: virgpio@11911180 {
				compatible = "starfive,jhb100-virgpio";
				reg = <0x0 0x11911180 0x0 0x500>;
				clocks = <&per0crg JHB100_PER0CLK_MAIN_ICG_EN_LTPI1>;
				gpio-controller;
				#gpio-cells = <2>;
				interrupts = <181>;
				interrupt-controller;
				#interrupt-cells = <2>;
				direction = "input";
				ngpios = <64>;
				label = "llgpi1";
				status = "disabled";
			};

			nlgpo1: virgpio@11912000 {
				compatible = "starfive,jhb100-virgpio";
				reg = <0x0 0x11912000 0x0 0x180>;
				clocks = <&per0crg JHB100_PER0CLK_MAIN_ICG_EN_LTPI1>;
				gpio-controller;
				#gpio-cells = <2>;
				direction = "output";
				ngpios = <256>;
				label = "nlgpo1";
				status = "disabled";
			};

			nlgpi1: virgpio@11912180 {
				compatible = "starfive,jhb100-virgpio";
				reg = <0x0 0x11912180 0x0 0x500>;
				clocks = <&per0crg JHB100_PER0CLK_MAIN_ICG_EN_LTPI1>;
				gpio-controller;
				#gpio-cells = <2>;
				interrupts = <182>;
				interrupt-controller;
				#interrupt-cells = <2>;
				direction = "input";
				ngpios = <256>;
				label = "nlgpi1";
				status = "disabled";
			};

			dma_uart: dma-controller@11924000 {
				compatible = "starfive,jhb100-axi-dma-uart";
				reg = <0x0 0x11924000 0x0 0x4000>;
				clocks = <&per0crg JHB100_PER0CLK_CORE_DMAC0>,
					<&per0crg JHB100_PER0CLK_MAIN_ICG_EN_DMAC_UART>;
				clock-names = "core-clk",  "cfgr-clk";
				resets = <&per0crg JHB100_PER0RST_MAIN_RSTN_DMAC0>;
				interrupts = <217>;
				#dma-cells = <1>;
				dma-channels = <16>;
				snps,dma-masters = <1>;
				snps,data-width = <3>;
				snps,block-size = <65536 65536 65536 65536 65536
						 65536 65536 65536 65536 65536
						 65536 65536 65536 65536 65536 65536>;
				snps,priority = <0 1 2 3 4 5 6 7 8
						 9 10 11 12 13 14 15>;
				snps,axi-max-burst-len = <16>;
				status = "disabled";
			};

			dma_i3c: dma-controller@11928000 {
				compatible = "starfive,jhb100-axi-dma-i3c";
				reg = <0x0 0x11928000 0x0 0x4000>;
				interrupts = <216>;
				clocks = <&per0crg JHB100_PER0CLK_CORE_DMAC2>,
					<&per0crg JHB100_PER0CLK_MAIN_ICG_EN_DMAC_I3C>;
				clock-names = "core-clk", "cfgr-clk";
				resets = <&per0crg JHB100_PER0RST_MAIN_RSTN_DMAC2>;
				#dma-cells = <3>;
				dma-channels = <16>;
				snps,dma-masters = <1>;
				snps,data-width = <3>;
				snps,block-size = <0x10000 0x10000 0x10000 0x10000
						   0x10000 0x10000 0x10000 0x10000
						   0x10000 0x10000 0x10000 0x10000
						   0x10000 0x10000 0x10000 0x10000>;
				snps,priority = <0x0 0x1 0x2 0x3 0x4 0x5 0x6 0x7
						 0x8 0x9 0xa 0xb 0xc 0xd 0xe 0xf>;
				snps,axi-max-burst-len = <16>;
				status = "disabled";
			};

			dma_i2c: dma-controller@1192c000 {
				compatible = "starfive,jhb100-axi-dma-i2c";
				reg = <0x0 0x1192c000 0x0 0x4000>;
				clocks = <&per0crg JHB100_PER0CLK_CORE_DMAC1>,
					<&per0crg JHB100_PER0CLK_MAIN_ICG_EN_DMAC_I2C>;
				clock-names = "core-clk", "cfgr-clk";
				resets = <&per0crg JHB100_PER0RST_MAIN_RSTN_DMAC1>;
				interrupts = <215>;
				#dma-cells = <1>;
				dma-channels = <32>;
				snps,dma-masters = <1>;
				snps,data-width = <3>;
				snps,block-size = <65536 65536 65536 65536 65536
						65536 65536 65536 65536 65536
						65536 65536 65536 65536 65536
						65536 65536 65536 65536 65536
						65536 65536 65536 65536 65536
						65536 65536 65536 65536 65536
						65536 65536>;
				snps,priority = <0 1 2 3 4 5 6 7 8 9 10 11
						12 13 14 15 16 17 18 19 20
						21 22 23 24 25 26 27 28 29
						30 31>;
				snps,axi-max-burst-len = <16>;
				status = "disabled";
			};

			uart4: serial@11980000 {
				compatible = "snps,dw-apb-uart";
				reg = <0x0 0x11980000 0x0 0x100>;
				clocks = <&per0crg JHB100_PER0CLK_SCLK_UART4>,
					<&per0crg JHB100_PER0CLK_APB_UART4>;
				clock-names = "baudclk", "apb_pclk";
				resets = <&per0crg JHB100_PER0RST_MAIN_RSTN_UART4>;
				interrupt-parent = <&intc>;
				interrupts = <24>;
				dmas = <&dma_uart 8>, <&dma_uart 9>;
				dma-names = "tx", "rx";
				reg-io-width = <4>;
				reg-shift = <2>;
				status = "disabled";
			};

			uart5: serial@11981000 {
				compatible = "snps,dw-apb-uart";
				reg = <0x0 0x11981000 0x0 0x400>;
				clocks = <&per0crg JHB100_PER0CLK_SCLK_UART5>,
					<&per0crg JHB100_PER0CLK_APB_UART5>;
				clock-names = "baudclk", "apb_pclk";
				resets = <&per0crg JHB100_PER0RST_MAIN_RSTN_UART5>;
				interrupt-parent = <&intc>;
				interrupts = <25>;
				dmas = <&dma_uart 10>, <&dma_uart 11>;
				dma-names = "tx", "rx";
				reg-io-width = <4>;
				reg-shift = <2>;
				status = "disabled";
			};

			uart6: serial@11982000 {
				compatible = "snps,dw-apb-uart";
				reg = <0x0 0x11982000 0x0 0x400>;
				clocks = <&per0crg JHB100_PER0CLK_SCLK_UART6>,
					<&per0crg JHB100_PER0CLK_APB_UART6>;
				clock-names = "baudclk", "apb_pclk";
				resets = <&per0crg JHB100_PER0RST_MAIN_RSTN_UART6>;
				interrupt-parent = <&intc>;
				interrupts = <26>;
				dmas = <&dma_uart 12>, <&dma_uart 13>;
				dma-names = "tx", "rx";
				reg-io-width = <4>;
				reg-shift = <2>;
				status = "disabled";
			};

			uart7: serial@11983000 {
				compatible = "snps,dw-apb-uart";
				reg = <0x0 0x11983000 0x0 0x400>;
				clocks = <&per0crg JHB100_PER0CLK_SCLK_UART7>,
					<&per0crg JHB100_PER0CLK_APB_UART7>;
				clock-names = "baudclk", "apb_pclk";
				resets = <&per0crg JHB100_PER0RST_MAIN_RSTN_UART7>;
				interrupt-parent = <&intc>;
				interrupts = <27>;
				dmas = <&dma_uart 14>, <&dma_uart 15>;
				dma-names = "tx", "rx";
				reg-io-width = <4>;
				reg-shift = <2>;
				status = "disabled";
			};

			uart8: serial@11984000 {
				compatible = "snps,dw-apb-uart";
				reg = <0x0 0x11984000 0x0 0x400>;
				clocks = <&per0crg JHB100_PER0CLK_SCLK_UART8>,
					<&per0crg JHB100_PER0CLK_APB_UART8>;
				clock-names = "baudclk", "apb_pclk";
				resets = <&per0crg JHB100_PER0RST_MAIN_RSTN_UART8>;
				interrupt-parent = <&intc>;
				interrupts = <28>;
				dmas = <&dma_uart 16>, <&dma_uart 17>;
				dma-names = "tx", "rx";
				reg-io-width = <4>;
				reg-shift = <2>;
				status = "disabled";
			};

			uart9: serial@11985000 {
				compatible = "snps,dw-apb-uart";
				reg = <0x0 0x11985000 0x0 0x400>;
				clocks = <&per0crg JHB100_PER0CLK_SCLK_UART9>,
					<&per0crg JHB100_PER0CLK_APB_UART9>;
				clock-names = "baudclk", "apb_pclk";
				resets = <&per0crg JHB100_PER0RST_MAIN_RSTN_UART9>;
				interrupt-parent = <&intc>;
				interrupts = <29>;
				dmas = <&dma_uart 18>, <&dma_uart 19>;
				dma-names = "tx", "rx";
				reg-io-width = <4>;
				reg-shift = <2>;
				status = "disabled";
			};

			uart10: serial@11986000 {
				compatible = "snps,dw-apb-uart";
				reg = <0x0 0x11986000 0x0 0x400>;
				clocks = <&per0crg JHB100_PER0CLK_SCLK_UART10>,
					<&per0crg JHB100_PER0CLK_APB_UART10>;
				clock-names = "baudclk", "apb_pclk";
				resets = <&per0crg JHB100_PER0RST_MAIN_RSTN_UART10>;
				interrupt-parent = <&intc>;
				interrupts = <30>;
				dmas = <&dma_uart 20>, <&dma_uart 21>;
				dma-names = "tx", "rx";
				reg-io-width = <4>;
				reg-shift = <2>;
				status = "disabled";
			};

			uart11: serial@11987000 {
				compatible = "snps,dw-apb-uart";
				reg = <0x0 0x11987000 0x0 0x400>;
				clocks = <&per0crg JHB100_PER0CLK_SCLK_UART11>,
					<&per0crg JHB100_PER0CLK_APB_UART11>;
				clock-names = "baudclk", "apb_pclk";
				resets = <&per0crg JHB100_PER0RST_MAIN_RSTN_UART11>;
				interrupt-parent = <&intc>;
				interrupts = <31>;
				dmas = <&dma_uart 22>, <&dma_uart 23>;
				dma-names = "tx", "rx";
				reg-io-width = <4>;
				reg-shift = <2>;
				status = "disabled";
			};

			uart12: serial@11988000 {
				compatible = "snps,dw-apb-uart";
				reg = <0x0 0x11988000 0x0 0x400>;
				clocks = <&per0crg JHB100_PER0CLK_SCLK_UART12>,
					<&per0crg JHB100_PER0CLK_APB_UART12>;
				clock-names = "baudclk", "apb_pclk";
				resets = <&per0crg JHB100_PER0RST_MAIN_RSTN_UART12>;
				interrupt-parent = <&intc>;
				interrupts = <32>;
				dmas = <&dma_uart 24>, <&dma_uart 25>;
				dma-names = "tx", "rx";
				reg-io-width = <4>;
				reg-shift = <2>;
				status = "disabled";
			};

			uart13: serial@11989000 {
				compatible = "snps,dw-apb-uart";
				reg = <0x0 0x11989000 0x0 0x400>;
				clocks = <&per0crg JHB100_PER0CLK_SCLK_UART13>,
					<&per0crg JHB100_PER0CLK_APB_UART13>;
				clock-names = "baudclk", "apb_pclk";
				resets = <&per0crg JHB100_PER0RST_MAIN_RSTN_UART13>;
				interrupt-parent = <&intc>;
				interrupts = <33>;
				dmas = <&dma_uart 26>, <&dma_uart 27>;
				dma-names = "tx", "rx";
				reg-io-width = <4>;
				reg-shift = <2>;
				status = "disabled";
			};

			uart14: serial@1198a000 {
				compatible = "snps,dw-apb-uart";
				reg = <0x0 0x1198a000 0x0 0x400>;
				clocks = <&per0crg JHB100_PER0CLK_SCLK_UART14>,
					<&per0crg JHB100_PER0CLK_APB_UART14>;
				clock-names = "baudclk", "apb_pclk";
				resets = <&per0crg JHB100_PER0RST_MAIN_RSTN_UART14>;
				interrupt-parent = <&intc>;
				interrupts = <34>;
				dmas = <&dma_uart 28>, <&dma_uart 29>;
				dma-names = "tx", "rx";
				reg-io-width = <4>;
				reg-shift = <2>;
				status = "disabled";
			};

			rng: rng@11a00000 {
				compatible = "starfive,jhb100-trng", "starfive,jh7110-trng";
				reg = <0x0 0x11a00000 0x0 0x4000>;
				clocks = <&per0crg JHB100_PER0CLK_HCLK_TRNG>,
					 <&per0crg JHB100_PER0CLK_MAIN_ICG_EN_TRNG>;
				clock-names = "hclk", "ahb";
				resets = <&per0crg JHB100_PER0RST_MAIN_RSTN_TRNG>;
				interrupts = <160>;
			};

			pinctrl_bmcperiph0: pinctrl@11a0a000 {
				compatible = "starfive,jhb100-sys-pinctrl-bmcperiph0";
				reg = <0x0 0x11a0a000 0x0 0x1000>;
				resets = <&per0crg JHB100_PER0RST_GPIO_IOMUX_PRESETN>;
				interrupts = <60>;
				interrupt-controller;
				#interrupt-cells = <2>;
				gpio-controller;
				#gpio-cells = <2>;
				gpio-ranges = <&pinctrl_bmcperiph0 0 0 60>;
			};

			timer0: timer@11a10000 {
				compatible = "starfive,jhb100-timer";
				reg = <0x0 0x11a10000 0x0 0x400>;
				interrupts = <149>, <150>;
				clocks = <&per0crg JHB100_PER0CLK_PCLK_DUALTIMER0>,
					<&per0crg JHB100_PER0CLK_TIMER0_DUALTIMER0>,
					<&per0crg JHB100_PER0CLK_TIMER1_DUALTIMER0>;
				clock-names = "apb", "ch0", "ch1";
				resets = <&per0crg JHB100_PER0RST_MAIN_RSTN_DUALTIMER0>;
				timer-id = <0>;
				status = "disabled";
			};

			timer1: timer@11a10400 {
				compatible = "starfive,jhb100-timer";
				reg = <0x0 0x11a10400 0x0 0x400>;
				interrupts = <151>, <152>;
				clocks = <&per0crg JHB100_PER0CLK_PCLK_DUALTIMER1>,
					<&per0crg JHB100_PER0CLK_TIMER0_DUALTIMER1>,
					<&per0crg JHB100_PER0CLK_TIMER1_DUALTIMER1>;
				clock-names = "apb", "ch0", "ch1";
				resets = <&per0crg JHB100_PER0RST_MAIN_RSTN_DUALTIMER1>;
				timer-id = <1>;
				status = "disabled";
			};

			timer2: timer@11a10800 {
				compatible = "starfive,jhb100-timer";
				reg = <0x0 0x11a10800 0x0 0x400>;
				interrupts = <153>, <154>;
				clocks = <&per0crg JHB100_PER0CLK_PCLK_DUALTIMER2>,
					<&per0crg JHB100_PER0CLK_TIMER0_DUALTIMER2>,
					<&per0crg JHB100_PER0CLK_TIMER1_DUALTIMER2>;
				clock-names = "apb", "ch0", "ch1";
				resets = <&per0crg JHB100_PER0RST_MAIN_RSTN_DUALTIMER2>;
				timer-id = <2>;
				status = "disabled";
			};

			wdt0: watchdog@11a11000 {
				compatible = "starfive,jhb100-wdt";
				reg = <0x0 0x11a11000 0x0 0x00000400>;
				interrupts = <155>;
				clocks = <&per0crg JHB100_PER0CLK_WDOGCLK_WDT0>,
					<&per0crg JHB100_PER0CLK_MAIN_ICG_EN_WDT0>;
				clock-names = "core", "apb";
				resets = <&per0crg JHB100_PER0RST_MAIN_RSTN_WDT0>;
				timeout_sec = <15>;
				status = "disabled";
			};

			wdt1: watchdog@11a11400 {
				compatible = "starfive,jhb100-wdt";
				reg = <0x0 0x11a11400 0x0 0x00000400>;
				interrupts = <156>;
				clocks = <&per0crg JHB100_PER0CLK_WDOGCLK_WDT1>,
					<&per0crg JHB100_PER0CLK_MAIN_ICG_EN_WDT1>;
				clock-names = "core", "apb";
				resets = <&per0crg JHB100_PER0RST_MAIN_RSTN_WDT1>;
				timeout_sec = <15>;
				status = "disabled";
			};

			wdt2: watchdog@11a11800 {
				compatible = "starfive,jhb100-wdt";
				reg = <0x0 0x11a11800 0x0 0x00000400>;
				interrupts = <157>;
				clocks = <&per0crg JHB100_PER0CLK_WDOGCLK_WDT2>,
					<&per0crg JHB100_PER0CLK_MAIN_ICG_EN_WDT2>;
				clock-names = "core", "apb";
				resets = <&per0crg JHB100_PER0RST_MAIN_RSTN_WDT2>;
				timeout_sec = <15>;
				status = "disabled";
			};

			wdt3: watchdog@11a11c00 {
				compatible = "starfive,jhb100-wdt";
				reg = <0x0 0x11a11c00 0x0 0x00000400>;
				interrupts = <158>;
				clocks = <&per0crg JHB100_PER0CLK_WDOGCLK_WDT3>,
					<&per0crg JHB100_PER0CLK_MAIN_ICG_EN_WDT3>;
				clock-names = "core", "apb";
				resets = <&per0crg JHB100_PER0RST_MAIN_RSTN_WDT3>;
				timeout_sec = <15>;
				status = "disabled";
			};

			wdt_ext: watchdog@11a12000 {
				compatible = "starfive,jhb100-wdt";
				reg = <0x0 0x11a12000 0x0 0x00000400>;
				interrupts = <159>;
				clocks = <&per0crg JHB100_PER0CLK_WDOGCLK_WDT_EXTERNAL>,
					<&per0crg JHB100_PER0CLK_MAIN_ICG_EN_WDT_EXTERNAL>;
				clock-names = "core", "apb";
				resets = <&per0crg JHB100_PER0RST_MAIN_RSTN_WDT4>;
				timeout_sec = <15>;
				status = "disabled";
			};

			i3c0: i3c@11a18000 {
				compatible = "starfive,jhb100-i3c";
				reg = <0x0 0x11a18000 0x0 0x600>;
				interrupts = <161>;
				clocks = <&per0crg JHB100_PER0CLK_CORE_I3C0>,
					<&per0crg JHB100_PER0CLK_MAIN_ICG_EN_I3C0>;
				clock-names = "ref", "pclk";
				resets = <&per0crg JHB100_PER0RST_MAIN_RSTN_I3C0>;
				reset-names = "core_rst";
				status = "disabled";
			};

			i3c1: i3c@11a18800 {
				compatible = "starfive,jhb100-i3c";
				reg = <0x0 0x11a18800 0x0 0x600>;
				interrupts = <162>;
				clocks = <&per0crg JHB100_PER0CLK_CORE_I3C1>,
					<&per0crg JHB100_PER0CLK_MAIN_ICG_EN_I3C1>;
				clock-names = "ref", "pclk";
				resets = <&per0crg JHB100_PER0RST_MAIN_RSTN_I3C1>;
				reset-names = "core_rst";
				status = "disabled";
			};

			i3c2: i3c@11a19000 {
				compatible = "starfive,jhb100-i3c";
				reg = <0x0 0x11a19000 0x0 0x600>;
				interrupts = <163>;
				clocks = <&per0crg JHB100_PER0CLK_CORE_I3C2>,
					<&per0crg JHB100_PER0CLK_MAIN_ICG_EN_I3C2>;
				clock-names = "ref", "pclk";
				resets = <&per0crg JHB100_PER0RST_MAIN_RSTN_I3C2>;
				reset-names = "core_rst";
				status = "disabled";
			};

			i3c3: i3c@11a19800 {
				compatible = "starfive,jhb100-i3c";
				reg = <0x0 0x11a19800 0x0 0x600>;
				interrupts = <164>;
				clocks = <&per0crg JHB100_PER0CLK_CORE_I3C3>,
					<&per0crg JHB100_PER0CLK_MAIN_ICG_EN_I3C3>;
				clock-names = "ref", "pclk";
				resets = <&per0crg JHB100_PER0RST_MAIN_RSTN_I3C3>;
				reset-names = "core_rst";
				status = "disabled";
			};

			i3c4: i3c@11a1a000 {
				compatible = "starfive,jhb100-i3c";
				reg = <0x0 0x11a1a000 0x0 0x600>;
				interrupts = <165>;
				clocks = <&per0crg JHB100_PER0CLK_CORE_I3C4>,
					<&per0crg JHB100_PER0CLK_MAIN_ICG_EN_I3C4>;
				clock-names = "ref", "pclk";
				resets = <&per0crg JHB100_PER0RST_MAIN_RSTN_I3C4>;
				reset-names = "core_rst";
				syscon = <&i3c4_syscon>;
				status = "disabled";
			};

			i3c4_syscon: i3c-syscon@11a1a600 {
				compatible = "syscon";
				reg = <0x0 0x11a1a600 0x0 0x4>;
				gpio-select = <GPIO_LEVEL_BIT GPIO_NORMAL>;
			};

			i3c5: i3c@11a1a800 {
				compatible = "starfive,jhb100-i3c";
				reg = <0x0 0x11a1a800 0x0 0x600>;
				interrupts = <166>;
				clocks = <&per0crg JHB100_PER0CLK_CORE_I3C5>,
					<&per0crg JHB100_PER0CLK_MAIN_ICG_EN_I3C5>;
				clock-names = "ref", "pclk";
				resets = <&per0crg JHB100_PER0RST_MAIN_RSTN_I3C5>;
				reset-names = "core_rst";
				syscon = <&i3c5_syscon>;
				status = "disabled";
			};

			i3c5_syscon: i3c-syscon@11a1ae00 {
				compatible = "syscon";
				reg = <0x0 0x11a1ae00 0x0 0x4>;
				gpio-select = <GPIO_LEVEL_BIT GPIO_NORMAL>;
			};

			i3c6: i3c@11a1b000 {
				compatible = "starfive,jhb100-i3c";
				reg = <0x0 0x11a1b000 0x0 0x600>;
				interrupts = <167>;
				clocks = <&per0crg JHB100_PER0CLK_CORE_I3C6>,
					<&per0crg JHB100_PER0CLK_MAIN_ICG_EN_I3C6>;
				clock-names = "ref", "pclk";
				resets = <&per0crg JHB100_PER0RST_MAIN_RSTN_I3C6>;
				reset-names = "core_rst";
				syscon = <&i3c6_syscon>;
				status = "disabled";
			};

			i3c6_syscon: i3c-syscon@11a1b600 {
				compatible = "syscon";
				reg = <0x0 0x11a1b600 0x0 0x4>;
				gpio-select = <GPIO_LEVEL_BIT GPIO_NORMAL>;
			};

			i3c7: i3c@11a1b800 {
				compatible = "starfive,jhb100-i3c";
				reg = <0x0 0x11a1b800 0x0 0x600>;
				interrupts = <168>;
				clocks = <&per0crg JHB100_PER0CLK_CORE_I3C7>,
					<&per0crg JHB100_PER0CLK_MAIN_ICG_EN_I3C7>;
				clock-names = "ref", "pclk";
				resets = <&per0crg JHB100_PER0RST_MAIN_RSTN_I3C7>;
				reset-names = "core_rst";
				syscon = <&i3c7_syscon>;
				status = "disabled";
			};

			i3c7_syscon: i3c-syscon@11a1be00 {
				compatible = "syscon";
				reg = <0x0 0x11a1be00 0x0 0x4>;
				gpio-select = <GPIO_LEVEL_BIT GPIO_NORMAL>;
			};

			i3c8: i3c@11a1c000 {
				compatible = "starfive,jhb100-i3c";
				reg = <0x0 0x11a1c000 0x0 0x600>;
				interrupts = <169>;
				clocks = <&per0crg JHB100_PER0CLK_CORE_I3C8>,
					<&per0crg JHB100_PER0CLK_MAIN_ICG_EN_I3C8>;
				clock-names = "ref", "pclk";
				resets = <&per0crg JHB100_PER0RST_MAIN_RSTN_I3C8>;
				reset-names = "core_rst";
				status = "disabled";
			};

			i3c9: i3c@11a1c800 {
				compatible = "starfive,jhb100-i3c";
				reg = <0x0 0x11a1c800 0x0 0x600>;
				interrupts = <170>;
				clocks = <&per0crg JHB100_PER0CLK_CORE_I3C9>,
					<&per0crg JHB100_PER0CLK_MAIN_ICG_EN_I3C9>;
				clock-names = "ref", "pclk";
				resets = <&per0crg JHB100_PER0RST_MAIN_RSTN_I3C9>;
				reset-names = "core_rst";
				status = "disabled";
			};

			i3c10: i3c@11a1d000 {
				compatible = "starfive,jhb100-i3c";
				reg = <0x0 0x11a1d000 0x0 0x600>;
				interrupts = <171>;
				clocks = <&per0crg JHB100_PER0CLK_CORE_I3C10>,
					<&per0crg JHB100_PER0CLK_MAIN_ICG_EN_I3C10>;
				clock-names = "ref", "pclk";
				resets = <&per0crg JHB100_PER0RST_MAIN_RSTN_I3C10>;
				reset-names = "core_rst";
				status = "disabled";
			};

			i3c11: i3c@11a1d800 {
				compatible = "starfive,jhb100-i3c";
				reg = <0x0 0x11a1d800 0x0 0x600>;
				interrupts = <172>;
				clocks = <&per0crg JHB100_PER0CLK_CORE_I3C11>,
					<&per0crg JHB100_PER0CLK_MAIN_ICG_EN_I3C11>;
				clock-names = "ref", "pclk";
				resets = <&per0crg JHB100_PER0RST_MAIN_RSTN_I3C11>;
				reset-names = "core_rst";
				status = "disabled";
			};

			i3c12: i3c@11a1e000 {
				compatible = "starfive,jhb100-i3c";
				reg = <0x0 0x11a1e000 0x0 0x600>;
				interrupts = <173>;
				clocks = <&per0crg JHB100_PER0CLK_CORE_I3C12>,
					<&per0crg JHB100_PER0CLK_MAIN_ICG_EN_I3C12>;
				clock-names = "ref", "pclk";
				resets = <&per0crg JHB100_PER0RST_MAIN_RSTN_I3C12>;
				reset-names = "core_rst";
				status = "disabled";
			};

			i3c13: i3c@11a1e800 {
				compatible = "starfive,jhb100-i3c";
				reg = <0x0 0x11a1e800 0x0 0x600>;
				interrupts = <174>;
				clocks = <&per0crg JHB100_PER0CLK_CORE_I3C13>,
					<&per0crg JHB100_PER0CLK_MAIN_ICG_EN_I3C13>;
				clock-names = "ref", "pclk";
				resets = <&per0crg JHB100_PER0RST_MAIN_RSTN_I3C13>;
				reset-names = "core_rst";
				status = "disabled";
			};

			i3c14: i3c@11a1f000 {
				compatible = "starfive,jhb100-i3c";
				reg = <0x0 0x11a1f000 0x0 0x600>;
				interrupts = <175>;
				clocks = <&per0crg JHB100_PER0CLK_CORE_I3C14>,
					<&per0crg JHB100_PER0CLK_MAIN_ICG_EN_I3C14>;
				clock-names = "ref", "pclk";
				resets = <&per0crg JHB100_PER0RST_MAIN_RSTN_I3C14>;
				reset-names = "core_rst";
				status = "disabled";
			};

			i3c15: i3c@11a1f800 {
				compatible = "starfive,jhb100-i3c";
				reg = <0x0 0x11a1f800 0x0 0x600>;
				interrupts = <176>;
				clocks = <&per0crg JHB100_PER0CLK_CORE_I3C15>,
					<&per0crg JHB100_PER0CLK_MAIN_ICG_EN_I3C15>;
				clock-names = "ref", "pclk";
				resets = <&per0crg JHB100_PER0RST_MAIN_RSTN_I3C15>;
				reset-names = "core_rst";
				status = "disabled";
			};

			i2c0_master: i2c@11a20000 {
				compatible = "starfive,jhb100-dwc-i2c-master", "snps,dwc-i2c";
				reg = <0x0 0x11a20000 0x0 0x400>;
				#address-cells = <1>;
				#size-cells = <0>;
				interrupts = <183>;
				clocks = <&per0crg JHB100_PER0CLK_MAIN_ICG_EN_I2C0>,
					<&per0crg JHB100_PER0CLK_APB_I2C0>;
				clock-names = "ref", "pclk";
				starfive,chsel = <0>;
				dwc-i2c-tx-fifo-depth = <64>;
				dwc-i2c-rx-fifo-depth = <64>;
				status = "disabled";
			};

			i2c0_slave: i2c@11a20400 {
				compatible = "starfive,jhb100-dwc-i2c-slave", "snps,dwc-i2c";
				reg = <0x0 0x11a20400 0x0 0x400>;
				#address-cells = <1>;
				#size-cells = <0>;
				interrupts = <184>;
				clocks = <&per0crg JHB100_PER0CLK_MAIN_ICG_EN_I2C0>,
					<&per0crg JHB100_PER0CLK_APB_I2C0>;
				clock-names = "ref", "pclk";
				dwc-i2c-tx-fifo-depth = <64>;
				dwc-i2c-rx-fifo-depth = <64>;
				status = "disabled";
			};

			i2c1_master: i2c@11a20800 {
				compatible = "starfive,jhb100-dwc-i2c-master", "snps,dwc-i2c";
				reg = <0x0 0x11a20800 0x0 0x400>;
				#address-cells = <1>;
				#size-cells = <0>;
				interrupts = <185>;
				clocks = <&per0crg JHB100_PER0CLK_MAIN_ICG_EN_I2C1>,
					<&per0crg JHB100_PER0CLK_APB_I2C1>;
				clock-names = "ref", "pclk";
				starfive,chsel = <0>;
				dwc-i2c-tx-fifo-depth = <64>;
				dwc-i2c-rx-fifo-depth = <64>;
				status = "disabled";
			};

			i2c1_slave: i2c@11a20c00 {
				compatible = "starfive,jhb100-dwc-i2c-slave", "snps,dwc-i2c";
				reg = <0x0 0x11a20c00 0x0 0x400>;
				#address-cells = <1>;
				#size-cells = <0>;
				interrupts = <186>;
				clocks = <&per0crg JHB100_PER0CLK_MAIN_ICG_EN_I2C1>,
					<&per0crg JHB100_PER0CLK_APB_I2C1>;
				clock-names = "ref", "pclk";
				dwc-i2c-tx-fifo-depth = <64>;
				dwc-i2c-rx-fifo-depth = <64>;
				status = "disabled";
			};

			i2c2_master: i2c@11a21000 {
				compatible = "starfive,jhb100-dwc-i2c-master", "snps,dwc-i2c";
				reg = <0x0 0x11a21000 0x0 0x400>;
				#address-cells = <1>;
				#size-cells = <0>;
				interrupts = <187>;
				clocks = <&per0crg JHB100_PER0CLK_MAIN_ICG_EN_I2C2>,
					<&per0crg JHB100_PER0CLK_APB_I2C2>;
				clock-names = "ref", "pclk";
				starfive,chsel = <0>;
				dwc-i2c-tx-fifo-depth = <64>;
				dwc-i2c-rx-fifo-depth = <64>;
				status = "disabled";
			};

			i2c2_slave: i2c@11a21400 {
				compatible = "starfive,jhb100-dwc-i2c-slave", "snps,dwc-i2c";
				reg = <0x0 0x11a21400 0x0 0x400>;
				#address-cells = <1>;
				#size-cells = <0>;
				interrupts = <188>;
				clocks = <&per0crg JHB100_PER0CLK_MAIN_ICG_EN_I2C2>,
					<&per0crg JHB100_PER0CLK_APB_I2C2>;
				clock-names = "ref", "pclk";
				dwc-i2c-tx-fifo-depth = <64>;
				dwc-i2c-rx-fifo-depth = <64>;
				status = "disabled";
			};

			i2c3_master: i2c@11a21800 {
				compatible = "starfive,jhb100-dwc-i2c-master", "snps,dwc-i2c";
				reg = <0x0 0x11a21800 0x0 0x400>;
				#address-cells = <1>;
				#size-cells = <0>;
				interrupts = <189>;
				clocks = <&per0crg JHB100_PER0CLK_MAIN_ICG_EN_I2C3>,
					<&per0crg JHB100_PER0CLK_APB_I2C3>;
				clock-names = "ref", "pclk";
				starfive,chsel = <0>;
				dwc-i2c-tx-fifo-depth = <64>;
				dwc-i2c-rx-fifo-depth = <64>;
				status = "disabled";
			};

			i2c3_slave: i2c@11a21c00 {
				compatible = "starfive,jhb100-dwc-i2c-slave", "snps,dwc-i2c";
				reg = <0x0 0x11a21c00 0x0 0x400>;
				#address-cells = <1>;
				#size-cells = <0>;
				interrupts = <190>;
				clocks = <&per0crg JHB100_PER0CLK_MAIN_ICG_EN_I2C3>,
					<&per0crg JHB100_PER0CLK_APB_I2C3>;
				clock-names = "ref", "pclk";
				dwc-i2c-tx-fifo-depth = <64>;
				dwc-i2c-rx-fifo-depth = <64>;
				status = "disabled";
			};

			i2c4_master: i2c@11a22000 {
				compatible = "starfive,jhb100-dwc-i2c-master", "snps,dwc-i2c";
				reg = <0x0 0x11a22000 0x0 0x400>;
				#address-cells = <1>;
				#size-cells = <0>;
				interrupts = <191>;
				clocks = <&per0crg JHB100_PER0CLK_MAIN_ICG_EN_I2C4>,
					<&per0crg JHB100_PER0CLK_APB_I2C4>;
				clock-names = "ref", "pclk";
				starfive,chsel = <0>;
				dwc-i2c-tx-fifo-depth = <64>;
				dwc-i2c-rx-fifo-depth = <64>;
				status = "disabled";
			};

			i2c4_slave: i2c@11a22400 {
				compatible = "starfive,jhb100-dwc-i2c-slave", "snps,dwc-i2c";
				reg = <0x0 0x11a22400 0x0 0x400>;
				#address-cells = <1>;
				#size-cells = <0>;
				interrupts = <192>;
				clocks = <&per0crg JHB100_PER0CLK_MAIN_ICG_EN_I2C4>,
					<&per0crg JHB100_PER0CLK_APB_I2C4>;
				clock-names = "ref", "pclk";
				dwc-i2c-tx-fifo-depth = <64>;
				dwc-i2c-rx-fifo-depth = <64>;
				status = "disabled";
			};

			i2c5_master: i2c@11a22800 {
				compatible = "starfive,jhb100-dwc-i2c-master", "snps,dwc-i2c";
				reg = <0x0 0x11a22800 0x0 0x400>;
				#address-cells = <1>;
				#size-cells = <0>;
				interrupts = <193>;
				clocks = <&per0crg JHB100_PER0CLK_MAIN_ICG_EN_I2C5>,
					<&per0crg JHB100_PER0CLK_APB_I2C5>;
				clock-names = "ref", "pclk";
				starfive,chsel = <0>;
				dwc-i2c-tx-fifo-depth = <64>;
				dwc-i2c-rx-fifo-depth = <64>;
				status = "disabled";
			};

			i2c5_slave: i2c5-slave@11a22c00 {
				compatible = "starfive,jhb100-dwc-i2c-slave", "snps,dwc-i2c";
				reg = <0x0 0x11a22c00 0x0 0x400>;
				#address-cells = <1>;
				#size-cells = <0>;
				interrupts = <194>;
				clocks = <&per0crg JHB100_PER0CLK_MAIN_ICG_EN_I2C5>,
					<&per0crg JHB100_PER0CLK_APB_I2C5>;
				clock-names = "ref", "pclk";
				dwc-i2c-tx-fifo-depth = <64>;
				dwc-i2c-rx-fifo-depth = <64>;
				status = "disabled";
			};

			i2c6_master: i2c6-master@11a23000 {
				compatible = "starfive,jhb100-dwc-i2c-master", "snps,dwc-i2c";
				reg = <0x0 0x11a23000 0x0 0x400>;
				#address-cells = <1>;
				#size-cells = <0>;
				interrupts = <195>;
				clocks = <&per0crg JHB100_PER0CLK_MAIN_ICG_EN_I2C6>,
					<&per0crg JHB100_PER0CLK_APB_I2C6>;
				clock-names = "ref", "pclk";
				starfive,chsel = <0>;
				dwc-i2c-tx-fifo-depth = <64>;
				dwc-i2c-rx-fifo-depth = <64>;
				status = "disabled";
			};

			i2c6_slave: i2c6-slave@11a23400 {
				compatible = "starfive,jhb100-dwc-i2c-slave", "snps,dwc-i2c";
				reg = <0x0 0x11a23400 0x0 0x400>;
				#address-cells = <1>;
				#size-cells = <0>;
				interrupts = <196>;
				clocks = <&per0crg JHB100_PER0CLK_MAIN_ICG_EN_I2C6>,
					<&per0crg JHB100_PER0CLK_APB_I2C6>;
				clock-names = "ref", "pclk";
				dwc-i2c-tx-fifo-depth = <64>;
				dwc-i2c-rx-fifo-depth = <64>;
				status = "disabled";
			};

			i2c7_master: i2c7-master@11a23800 {
				compatible = "starfive,jhb100-dwc-i2c-master", "snps,dwc-i2c";
				reg = <0x0 0x11a23800 0x0 0x400>;
				#address-cells = <1>;
				#size-cells = <0>;
				interrupts = <197>;
				clocks = <&per0crg JHB100_PER0CLK_MAIN_ICG_EN_I2C7>,
					<&per0crg JHB100_PER0CLK_APB_I2C7>;
				clock-names = "ref", "pclk";
				starfive,chsel = <0>;
				dwc-i2c-tx-fifo-depth = <64>;
				dwc-i2c-rx-fifo-depth = <64>;
				status = "disabled";
			};

			i2c7_slave: i2c7-slave@11a23c00 {
				compatible = "starfive,jhb100-dwc-i2c-slave", "snps,dwc-i2c";
				reg = <0x0 0x11a23c00 0x0 0x400>;
				#address-cells = <1>;
				#size-cells = <0>;
				interrupts = <198>;
				clocks = <&per0crg JHB100_PER0CLK_MAIN_ICG_EN_I2C7>,
					<&per0crg JHB100_PER0CLK_APB_I2C7>;
				clock-names = "ref", "pclk";
				dwc-i2c-tx-fifo-depth = <64>;
				dwc-i2c-rx-fifo-depth = <64>;
				status = "disabled";
			};

			i2c8_master: i2c8-master@11a24000 {
				compatible = "starfive,jhb100-dwc-i2c-master", "snps,dwc-i2c";
				reg = <0x0 0x11a24000 0x0 0x400>;
				#address-cells = <1>;
				#size-cells = <0>;
				interrupts = <199>;
				clocks = <&per0crg JHB100_PER0CLK_MAIN_ICG_EN_I2C8>,
					<&per0crg JHB100_PER0CLK_APB_I2C8>;
				clock-names = "ref", "pclk";
				starfive,chsel = <0>;
				dwc-i2c-tx-fifo-depth = <64>;
				dwc-i2c-rx-fifo-depth = <64>;
				status = "disabled";
			};

			i2c8_slave: i2c8-slave@11a24400 {
				compatible = "starfive,jhb100-dwc-i2c-slave", "snps,dwc-i2c";
				reg = <0x0 0x11a24400 0x0 0x400>;
				#address-cells = <1>;
				#size-cells = <0>;
				interrupts = <200>;
				clocks = <&per0crg JHB100_PER0CLK_MAIN_ICG_EN_I2C8>,
					<&per0crg JHB100_PER0CLK_APB_I2C8>;
				clock-names = "ref", "pclk";
				dwc-i2c-tx-fifo-depth = <64>;
				dwc-i2c-rx-fifo-depth = <64>;
				status = "disabled";
			};

			i2c9_master: i2c9-master@11a24800 {
				compatible = "starfive,jhb100-dwc-i2c-master", "snps,dwc-i2c";
				reg = <0x0 0x11a24800 0x0 0x400>;
				#address-cells = <1>;
				#size-cells = <0>;
				interrupts = <201>;
				clocks = <&per0crg JHB100_PER0CLK_MAIN_ICG_EN_I2C9>,
					<&per0crg JHB100_PER0CLK_APB_I2C9>;
				clock-names = "ref", "pclk";
				starfive,chsel = <0>;
				dwc-i2c-tx-fifo-depth = <64>;
				dwc-i2c-rx-fifo-depth = <64>;
				status = "disabled";
			};

			i2c9_slave: i2c@11a24c00 {
				compatible = "starfive,jhb100-dwc-i2c-slave", "snps,dwc-i2c";
				reg = <0x0 0x11a24c00 0x0 0x400>;
				#address-cells = <1>;
				#size-cells = <0>;
				interrupts = <202>;
				clocks = <&per0crg JHB100_PER0CLK_MAIN_ICG_EN_I2C9>,
					<&per0crg JHB100_PER0CLK_APB_I2C9>;
				clock-names = "ref", "pclk";
				dwc-i2c-tx-fifo-depth = <64>;
				dwc-i2c-rx-fifo-depth = <64>;
				status = "disabled";
			};

			i2c10_master: i2c@11a25000 {
				compatible = "starfive,jhb100-dwc-i2c-master", "snps,dwc-i2c";
				reg = <0x0 0x11a25000 0x0 0x400>;
				#address-cells = <1>;
				#size-cells = <0>;
				interrupts = <203>;
				clocks = <&per0crg JHB100_PER0CLK_MAIN_ICG_EN_I2C10>,
					<&per0crg JHB100_PER0CLK_APB_I2C10>;
				clock-names = "ref", "pclk";
				starfive,chsel = <0>;
				dwc-i2c-tx-fifo-depth = <64>;
				dwc-i2c-rx-fifo-depth = <64>;
				status = "disabled";
			};

			i2c10_slave: i2c@11a25400 {
				compatible = "starfive,jhb100-dwc-i2c-slave", "snps,dwc-i2c";
				reg = <0x0 0x11a25400 0x0 0x400>;
				#address-cells = <1>;
				#size-cells = <0>;
				interrupts = <204>;
				clocks = <&per0crg JHB100_PER0CLK_MAIN_ICG_EN_I2C10>,
					<&per0crg JHB100_PER0CLK_APB_I2C10>;
				clock-names = "ref", "pclk";
				dwc-i2c-tx-fifo-depth = <64>;
				dwc-i2c-rx-fifo-depth = <64>;
				status = "disabled";
			};

			i2c11_master: i2c@11a25800 {
				compatible = "starfive,jhb100-dwc-i2c-master", "snps,dwc-i2c";
				reg = <0x0 0x11a25800 0x0 0x400>;
				#address-cells = <1>;
				#size-cells = <0>;
				interrupts = <205>;
				clocks = <&per0crg JHB100_PER0CLK_MAIN_ICG_EN_I2C11>,
					<&per0crg JHB100_PER0CLK_APB_I2C11>;
				clock-names = "ref", "pclk";
				starfive,chsel = <0>;
				dwc-i2c-tx-fifo-depth = <64>;
				dwc-i2c-rx-fifo-depth = <64>;
				status = "disabled";
			};

			i2c11_slave: i2c@11a25c00 {
				compatible = "starfive,jhb100-dwc-i2c-slave", "snps,dwc-i2c";
				reg = <0x0 0x11a25c00 0x0 0x400>;
				#address-cells = <1>;
				#size-cells = <0>;
				interrupts = <206>;
				clocks = <&per0crg JHB100_PER0CLK_MAIN_ICG_EN_I2C11>,
					<&per0crg JHB100_PER0CLK_APB_I2C11>;
				clock-names = "ref", "pclk";
				dwc-i2c-tx-fifo-depth = <64>;
				dwc-i2c-rx-fifo-depth = <64>;
				status = "disabled";
			};

			i2c12_master: i2c@11a26000 {
				compatible = "starfive,jhb100-dwc-i2c-master", "snps,dwc-i2c";
				reg = <0x0 0x11a26000 0x0 0x400>;
				#address-cells = <1>;
				#size-cells = <0>;
				interrupts = <207>;
				clocks = <&per0crg JHB100_PER0CLK_MAIN_ICG_EN_I2C12>,
					<&per0crg JHB100_PER0CLK_APB_I2C12>;
				clock-names = "ref", "pclk";
				starfive,chsel = <0>;
				dwc-i2c-tx-fifo-depth = <64>;
				dwc-i2c-rx-fifo-depth = <64>;
				status = "disabled";
			};

			i2c12_slave: i2c@11a26400 {
				compatible = "starfive,jhb100-dwc-i2c-slave", "snps,dwc-i2c";
				reg = <0x0 0x11a26400 0x0 0x400>;
				#address-cells = <1>;
				#size-cells = <0>;
				interrupts = <208>;
				clocks = <&per0crg JHB100_PER0CLK_MAIN_ICG_EN_I2C12>,
					<&per0crg JHB100_PER0CLK_APB_I2C12>;
				clock-names = "ref", "pclk";
				dwc-i2c-tx-fifo-depth = <64>;
				dwc-i2c-rx-fifo-depth = <64>;
				status = "disabled";
			};

			i2c13_master: i2c@11a26800 {
				compatible = "starfive,jhb100-dwc-i2c-master", "snps,dwc-i2c";
				reg = <0x0 0x11a26800 0x0 0x400>;
				#address-cells = <1>;
				#size-cells = <0>;
				interrupts = <209>;
				clocks = <&per0crg JHB100_PER0CLK_MAIN_ICG_EN_I2C13>,
					<&per0crg JHB100_PER0CLK_APB_I2C13>;
				clock-names = "ref", "pclk";
				starfive,chsel = <0>;
				dwc-i2c-tx-fifo-depth = <64>;
				dwc-i2c-rx-fifo-depth = <64>;
				status = "disabled";
			};

			i2c13_slave: i2c@11a26c00 {
				compatible = "starfive,jhb100-dwc-i2c-slave", "snps,dwc-i2c";
				reg = <0x0 0x11a26c00 0x0 0x400>;
				#address-cells = <1>;
				#size-cells = <0>;
				interrupts = <210>;
				clocks = <&per0crg JHB100_PER0CLK_MAIN_ICG_EN_I2C13>,
					<&per0crg JHB100_PER0CLK_APB_I2C13>;
				clock-names = "ref", "pclk";
				dwc-i2c-tx-fifo-depth = <64>;
				dwc-i2c-rx-fifo-depth = <64>;
				status = "disabled";
			};

			i2c14_master: i2c@11a27000 {
				compatible = "starfive,jhb100-dwc-i2c-master", "snps,dwc-i2c";
				reg = <0x0 0x11a27000 0x0 0x400>;
				#address-cells = <1>;
				#size-cells = <0>;
				interrupts = <211>;
				clocks = <&per0crg JHB100_PER0CLK_MAIN_ICG_EN_I2C14>,
					<&per0crg JHB100_PER0CLK_APB_I2C14>;
				clock-names = "ref", "pclk";
				starfive,chsel = <0>;
				dwc-i2c-tx-fifo-depth = <64>;
				dwc-i2c-rx-fifo-depth = <64>;
				status = "disabled";
			};

			i2c14_slave: i2c@11a27400 {
				compatible = "starfive,jhb100-dwc-i2c-slave", "snps,dwc-i2c";
				reg = <0x0 0x11a27400 0x0 0x400>;
				#address-cells = <1>;
				#size-cells = <0>;
				interrupts = <212>;
				clocks = <&per0crg JHB100_PER0CLK_MAIN_ICG_EN_I2C14>,
					<&per0crg JHB100_PER0CLK_APB_I2C14>;
				clock-names = "ref", "pclk";
				dwc-i2c-tx-fifo-depth = <64>;
				dwc-i2c-rx-fifo-depth = <64>;
				status = "disabled";
			};

			i2c15_master: i2c@11a27800 {
				compatible = "starfive,jhb100-dwc-i2c-master", "snps,dwc-i2c";
				reg = <0x0 0x11a27800 0x0 0x400>;
				#address-cells = <1>;
				#size-cells = <0>;
				interrupts = <213>;
				clocks = <&per0crg JHB100_PER0CLK_MAIN_ICG_EN_I2C15>,
					<&per0crg JHB100_PER0CLK_APB_I2C15>;
				clock-names = "ref", "pclk";
				starfive,chsel = <0>;
				dwc-i2c-tx-fifo-depth = <64>;
				dwc-i2c-rx-fifo-depth = <64>;
				status = "disabled";
			};

			i2c15_slave: i2c@11a27c00 {
				compatible = "starfive,jhb100-dwc-i2c-slave", "snps,dwc-i2c";
				reg = <0x0 0x11a27c00 0x0 0x400>;
				#address-cells = <1>;
				#size-cells = <0>;
				interrupts = <214>;
				clocks = <&per0crg JHB100_PER0CLK_MAIN_ICG_EN_I2C15>,
					<&per0crg JHB100_PER0CLK_APB_I2C15>;
				clock-names = "ref", "pclk";
				dwc-i2c-tx-fifo-depth = <64>;
				dwc-i2c-rx-fifo-depth = <64>;
				status = "disabled";
			};

			sol4: sol@11a40000 {
				compatible = "starfive,jhb100-sol";
				reg = <0x0 0x11a40000 0x0 0x400>;
				interrupt-parent = <&intc>;
				interrupts = <9>;
				clocks = <&per0crg JHB100_PER0CLK_MAIN_ICG_EN_SOL4>;
				resets = <&per0crg JHB100_PER0RST_MAIN_RSTN_SOL4>;
				status = "disabled";
			};

			sol5: sol@11a40400 {
				compatible = "starfive,jhb100-sol";
				reg = <0x0 0x11a40400 0x0 0x400>;
				interrupt-parent = <&intc>;
				interrupts = <10>;
				clocks = <&per0crg JHB100_PER0CLK_MAIN_ICG_EN_SOL5>;
				resets = <&per0crg JHB100_PER0RST_MAIN_RSTN_SOL5>;
				status = "disabled";
			};

			sol6: sol@11a40800 {
				compatible = "starfive,jhb100-sol";
				reg = <0x0 0x11a40800 0x0 0x400>;
				interrupt-parent = <&intc>;
				interrupts = <11>;
				clocks = <&per0crg JHB100_PER0CLK_MAIN_ICG_EN_SOL6>;
				resets = <&per0crg JHB100_PER0RST_MAIN_RSTN_SOL6>;
				status = "disabled";
			};

			sol7: sol@11a40c00 {
				compatible = "starfive,jhb100-sol";
				reg = <0x0 0x11a40c00 0x0 0x400>;
				interrupt-parent = <&intc>;
				interrupts = <12>;
				clocks = <&per0crg JHB100_PER0CLK_MAIN_ICG_EN_SOL7>;
				resets = <&per0crg JHB100_PER0RST_MAIN_RSTN_SOL7>;
				status = "disabled";
			};

			sol8: sol@11a41000 {
				compatible = "starfive,jhb100-sol";
				reg = <0x0 0x11a41000 0x0 0x400>;
				interrupt-parent = <&intc>;
				interrupts = <13>;
				clocks = <&per0crg JHB100_PER0CLK_MAIN_ICG_EN_SOL8>;
				resets = <&per0crg JHB100_PER0RST_MAIN_RSTN_SOL8>;
				status = "disabled";
			};

			sol9: sol@11a41400 {
				compatible = "starfive,jhb100-sol";
				reg = <0x0 0x11a41400 0x0 0x400>;
				interrupt-parent = <&intc>;
				interrupts = <14>;
				clocks = <&per0crg JHB100_PER0CLK_MAIN_ICG_EN_SOL9>;
				resets = <&per0crg JHB100_PER0RST_MAIN_RSTN_SOL9>;
				status = "disabled";
			};

			sol10: sol@11a41800 {
				compatible = "starfive,jhb100-sol";
				reg = <0x0 0x11a41800 0x0 0x400>;
				interrupt-parent = <&intc>;
				interrupts = <15>;
				clocks = <&per0crg JHB100_PER0CLK_MAIN_ICG_EN_SOL10>;
				resets = <&per0crg JHB100_PER0RST_MAIN_RSTN_SOL10>;
				status = "disabled";
			};

			sol11: sol@11a41c00 {
				compatible = "starfive,jhb100-sol";
				reg = <0x0 0x11a41c00 0x0 0x400>;
				interrupt-parent = <&intc>;
				interrupts = <16>;
				clocks = <&per0crg JHB100_PER0CLK_MAIN_ICG_EN_SOL11>;
				resets = <&per0crg JHB100_PER0RST_MAIN_RSTN_SOL11>;
				status = "disabled";
			};

			sol12: sol@11a42000 {
				compatible = "starfive,jhb100-sol";
				reg = <0x0 0x11a42000 0x0 0x400>;
				interrupt-parent = <&intc>;
				interrupts = <17>;
				clocks = <&per0crg JHB100_PER0CLK_MAIN_ICG_EN_SOL12>;
				resets = <&per0crg JHB100_PER0RST_MAIN_RSTN_SOL12>;
				status = "disabled";
			};

			sol13: sol@11a42400 {
				compatible = "starfive,jhb100-sol";
				reg = <0x0 0x11a42400 0x0 0x400>;
				interrupt-parent = <&intc>;
				interrupts = <18>;
				clocks = <&per0crg JHB100_PER0CLK_MAIN_ICG_EN_SOL13>;
				resets = <&per0crg JHB100_PER0RST_MAIN_RSTN_SOL13>;
				status = "disabled";
			};

			sol14: sol@11a42800 {
				compatible = "starfive,jhb100-sol";
				reg = <0x0 0x11a42800 0x0 0x400>;
				interrupt-parent = <&intc>;
				interrupts = <19>;
				clocks = <&per0crg JHB100_PER0CLK_MAIN_ICG_EN_SOL14>;
				resets = <&per0crg JHB100_PER0RST_MAIN_RSTN_SOL14>;
				status = "disabled";
			};

			uart_routing: uart-routing@11a42a00 {
				compatible = "starfive,jhb100-uart-routing";
				reg = <0x0 0x11a42a00 0x0 0x100>;
				status = "disabled";
			};

			dma_sfc0: dma-controller@11a80000 {
				compatible = "starfive,jhb100-axi-dma-sfc";
				reg = <0x0 0x11a80000 0x0 0x400>;
				clocks = <&per1crg JHB100_PER1CLK_DMAC1_1CH_CORE>,
					<&per1crg JHB100_PER1CLK_DMAC1_1CH_ACLK>;
				clock-names = "core-clk", "cfgr-clk";
				resets = <&per1crg JHB100_PER1RST_MAIN_RSTN_DMAC_SFC0>;
				interrupts = <120>;
				#dma-cells = <3>;
				dma-channels = <1>;
				snps,dma-masters = <1>;
				snps,data-width = <3>;
				snps,block-size = <65536>;
				snps,priority = <0>;
				snps,axi-max-burst-len = <16>;
				status = "disabled";
			};

			dma_sfc1: dma-controller@11a80400 {
				compatible = "starfive,jhb100-axi-dma-sfc";
				reg = <0x0 0x11a80400 0x0 0x400>;
				clocks = <&per1crg JHB100_PER1CLK_DMAC2_1CH_CORE>,
					<&per1crg JHB100_PER1CLK_DMAC2_1CH_ACLK>;
				clock-names = "core-clk", "cfgr-clk";
				resets = <&per1crg JHB100_PER1RST_MAIN_RSTN_DMAC_SFC1>;
				interrupts = <121>;
				#dma-cells = <3>;
				dma-channels = <1>;
				snps,dma-masters = <1>;
				snps,data-width = <3>;
				snps,block-size = <65536>;
				snps,priority = <0>;
				snps,axi-max-burst-len = <16>;
				status = "disabled";
			};

			dma_sfc2: dma-controller@11a80800 {
				compatible = "starfive,jhb100-axi-dma-sfc";
				reg = <0x0 0x11a80800 0x0 0x400>;
				clocks = <&per1crg JHB100_PER1CLK_DMAC3_1CH_CORE>,
					<&per1crg JHB100_PER1CLK_DMAC3_1CH_ACLK>;
				clock-names = "core-clk", "cfgr-clk";
				resets = <&per1crg JHB100_PER1RST_MAIN_RSTN_DMAC_SFC2>;
				interrupts = <122>;
				#dma-cells = <3>;
				dma-channels = <1>;
				snps,dma-masters = <1>;
				snps,data-width = <3>;
				snps,block-size = <65536>;
				snps,priority = <0>;
				snps,axi-max-burst-len = <16>;
			};

			dma_spi0: dma-controller@11a80c00 {
				compatible = "starfive,jhb100-axi-dma-spi";
				reg = <0x0 0x11a80c00 0x0 0x400>;
				clocks = <&per1crg JHB100_PER1CLK_DMAC0_2CH_CORE>,
					<&per1crg JHB100_PER1CLK_DMAC0_2CH_ACLK>;
				clock-names = "core-clk", "cfgr-clk";
				resets = <&per1crg JHB100_PER1RST_MAIN_RSTN_DMAC_SPI0>;
				interrupts = <123>;
				#dma-cells = <1>;
				dma-channels = <2>;
				snps,dma-masters = <1>;
				snps,data-width = <3>;
				snps,block-size = <65536 65536>;
				snps,priority = <0 1>;
				snps,axi-max-burst-len = <16>;
				status = "disabled";
			};

			sgpio0: sgpio@11a81000 {
				#gpio-cell = <2>;
				gpio-controller;
				compatible = "starfive,jhb100-sgpio";
				reg = <0x0 0x11a81000 0x0 0x400>;
				clocks = <&per1crg JHB100_PER1CLK_MAIN_ICG_EN_SGPIO0>,
					 <&per1crg JHB100_PER1CLK_SGPIO0_DCLK>;
				clock-names = "mclk", "dclk";
				resets = <&per1crg JHB100_PER1RST_MAIN_RSTN_SGPIO0>;
				interrupts = <114>;
				interrupt-controller;
				#interrupt-cells = <2>;
				ngpios = <128>;
				bus-frequency = <1200000>;
				use-hw-data;
				status = "disabled";
			};

			sgpio1: sgpio@11a81400 {
				#gpio-cell = <2>;
				gpio-controller;
				compatible = "starfive,jhb100-sgpio";
				reg = <0x0 0x11a81400 0x0 0x400>;
				clocks = <&per1crg JHB100_PER1CLK_MAIN_ICG_EN_SGPIO1>,
					 <&per1crg JHB100_PER1CLK_SGPIO1_DCLK>;
				clock-names = "mclk", "dclk";
				resets = <&per1crg JHB100_PER1RST_MAIN_RSTN_SGPIO1>;
				interrupts = <115>;
				interrupt-controller;
				#interrupt-cells = <2>;
				ngpios = <128>;
				bus-frequency = <1200000>;
				use-hw-data;
				status = "disabled";
			};

			ufs0: ufs@11b10000 {
				compatible = "starfive,jhb100-ufs", "jedec,ufs-3.1";
				reg = <0x0 0x11b10000 0x0 0x10000>;
				interrupts = <104>, <105>;
				interrupts-names = "ufs", "err";
				clocks = <&per1crg JHB100_PER1CLK_UFS_REF>,
					 <&per1crg JHB100_PER1CLK_UFS_150>,
					 <&per1crg JHB100_PER1CLK_UFS_300>,
					 <&per1crg JHB100_PER1CLK_UFS_400>,
					 <&per1crg JHB100_PER1CLK_UFS_75>,
					 <&per1crg JHB100_PER1CLK_UFS_37_5>,
					 <&per1crg JHB100_PER1CLK_UFS_7_5>,
					 <&per1crg JHB100_PER1CLK_UFS_1_875>,
					 <&per1crg JHB100_PER1CLK_UFS_7_143>,
					 <&per1crg JHB100_PER1CLK_UFS_3_5715>,
					 <&per1crg JHB100_PER1CLK_MAIN_ICG_EN_UFS>;
				clock-names = "ref_clk","clk_150", "clk_300","clk_400",
					      "clk_75", "clk_37_5", "clk_7_5","clk_1_875",
					      "clk_7_143", "clk_3_5715", "ufs";
				freq-table-hz = <26000000 26000000>,
						<50000000 150000000>,
						<300000000 300000000>,
						<400000000 400000000>,
						<75000000 75000000>,
						<37500000 37500000>,
						<7500000 7500000>,
						<1875000 1875000>,
						<7143000 7143000>,
						<3571500 3571500>;
				resets = <&per1crg JHB100_PER1RST_MAIN_RSTN_UFS>,
					 <&per1crg JHB100_PER1RST_MAIN_RSTN_UFS_PHY>;
				reset-names = "main", "phy";
				starfive,syscon = <&per1_syscon>;
				hwlocks = <&hwspinlock 1>;
				status = "disabled";
			};

			pinctrl_bmcperiph1: pinctrl@11b42000 {
				compatible = "starfive,jhb100-sys-pinctrl-bmcperiph1";
				reg = <0x0 0x11b42000 0x0 0x800>;
				resets = <&per1crg JHB100_PER1RST_IOMUX_PRESETN>;
				interrupts = <61>;
				interrupt-controller;
				#interrupt-cells = <2>;
				gpio-controller;
				#gpio-cells = <2>;
				gpio-ranges = <&pinctrl_bmcperiph1 0 0 36>;
			};

			pinctrl_emmc: emmc@11b42800 {
				compatible = "starfive,jhb100-pinctrl-emmc";
				reg = <0x0 0x11b42800 0x0 0x800>;
				interrupts = <119>;
				interrupt-controller;
				#interrupt-cells = <2>;
				gpio-controller;
				#gpio-cells = <2>;
				gpio-ranges = <&pinctrl_emmc 0 0 12>;
			};


			pinctrl_bmcperiph2: pinctrl@11bc2000 {
				compatible = "starfive,jhb100-sys-pinctrl-bmcperiph2";
				reg = <0x0 0x11bc2000 0x0 0x400>;
				resets = <&per2crg JHB100_PER2RST_IOMUX_PRESETN>;
				interrupts = <62>;
				interrupt-controller;
				#interrupt-cells = <2>;
				gpio-controller;
				#gpio-cells = <2>;
				gpio-ranges = <&pinctrl_bmcperiph2 0 0 31>;
			};

			pinctrl_bmcperiph2_pok: pinctrl@11bc2400 {
				compatible = "starfive,jhb100-sys-pinctrl-bmcperiph2-pok";
				reg = <0x0 0x11bc2400 0x0 0x400>;
				resets = <&per2crg JHB100_PER2RST_POK_IOMUX_PRESETN>;
				interrupts = <63>;
				interrupt-controller;
				#interrupt-cells = <2>;
				gpio-controller;
				#gpio-cells = <2>;
				gpio-ranges = <&pinctrl_bmcperiph2_pok 0 0 18>;
			};

			pinctrl_adc0: pinctrl@11bc2800 {
				compatible = "starfive,jhb100-pinctrl-adc0";
				reg = <0x0 0x11bc2800 0x0 0x400>;
				resets = <&per2crg JHB100_PER2RST_ADC0_IOMUX_PRESETN>;
				interrupts = <147>;
				interrupt-controller;
				#interrupt-cells = <2>;
				gpio-controller;
				#gpio-cells = <2>;
				gpio-ranges = <&pinctrl_adc0 0 0 8>;
			};

			pinctrl_adc1: pinctrl@11bc2c00 {
				compatible = "starfive,jhb100-pinctrl-adc1";
				reg = <0x0 0x11bc2c00 0x0 0x400>;
				resets = <&per2crg JHB100_PER2RST_ADC1_IOMUX_PRESETN>;
				interrupts = <148>;
				interrupt-controller;
				#interrupt-cells = <2>;
				gpio-controller;
				#gpio-cells = <2>;
				gpio-ranges = <&pinctrl_adc1 0 0 8>;
			};

			can0: can@11bc4000 {
				compatible = "ipms,canfd";
				reg = <0x0 0x11bc4000 0x0 0x2000>;
				interrupts = <143>;
				clocks = <&per2crg JHB100_PER2CLK_CAN0_CORE_DIV>,
					<&per2crg JHB100_PER2CLK_MAIN_ICG_EN_CAN0>;
				clock-names = "core_clk", "main_clk";
				resets = <&per2crg JHB100_PER2RST_MAIN_RSTN_CAN0>;
				starfive,sys-syscon = <&syscon_bmcperiph2 0x50 0x0 0x1>;
				status = "disabled";
			};

			can1: can@11bc6000 {
				compatible = "ipms,canfd";
				reg = <0x0 0x11bc6000 0x0 0x2000>;
				interrupts = <144>;
				clocks = <&per2crg JHB100_PER2CLK_CAN1_CORE_DIV>,
					<&per2crg JHB100_PER2CLK_MAIN_ICG_EN_CAN1>;
				clock-names = "core_clk", "main_clk";
				resets = <&per2crg JHB100_PER2RST_MAIN_RSTN_CAN1>;
				starfive,sys-syscon = <&syscon_bmcperiph2 0x60 0x0 0x1>;
				status = "disabled";
			};

			pwm_tach: pwm-tach-controller@11be0000 {
				compatible = "starfive,jhb100-pwm-tach";
				reg = <0x0 0x11be0000 0x0 0x400>;
				interrupts = <128>;
				clocks = <&per2crg JHB100_PER2CLK_FAN_TACH_PCLK>;
				resets = <&per2crg JHB100_PER2RST_FAN_TACH_PRESETN>;
				status = "disabled";
			};

			pwm: pwm@11be0400 {
				compatible = "starfive,jhb100-pwm", "starfive,jh7110-pwm", "opencores,pwm-v1";
				reg = <0x0 0x11be0400 0x0 0x400>;
				clocks = <&pwm_apb>;
				#pwm-cells = <3>;
				status = "disabled";
			};

			rtc: rtc@11be1300 {
				compatible = "starfive,jhb100-rtc", "starfive,jh7110-rtc";
				reg = <0x0 0x11be1300 0x0 0x100>;
				interrupts = <142>;
				interrupt-names = "rtc";
				clocks = <&rtc_apb>, <&osc>;
				clock-names = "pclk", "cal_clk";
				resets = <&per2crg JHB100_PER2RST_MAIN_RSTN_RTC>;
				rtc,cal-clock-freq = <1000000>;
				status = "disabled";
			};

			adc0: saradc@11be1400 {
				compatible = "starfive,jhb100-saradc";
				reg = <0x0 0x11be1400 0x0 0x400>;
				interrupts = <145>;
				clocks = <&per2crg JHB100_PER2CLK_MAIN_ICG_EN_ADC0>;
				resets = <&per2crg JHB100_PER2RST_ADC0_PRESETN>;
				#io-channel-cells = <1>;
				upper-bound = <0xfff>;
				lower-bound = <0>;
				/* Cycle time = (scan-freq + 5) * 10 ns, minimum scan-freq is 15 */
				scan-freq = <20>;
				status = "disabled";
			};

			adc1: saradc@11be1800 {
				compatible = "starfive,jhb100-saradc";
				reg = <0x0 0x11be1800 0x0 0x400>;
				interrupts = <146>;
				clocks = <&per2crg JHB100_PER2CLK_MAIN_ICG_EN_ADC1>;
				resets = <&per2crg JHB100_PER2RST_ADC1_PRESETN>;
				#io-channel-cells = <1>;
				upper-bound = <0xfff>;
				lower-bound = <0>;
				/* Cycle time = (scan-freq + 5) * 10 ns, minimum scan-freq is 15 */
				scan-freq = <20>;
				status = "disabled";
			};

			pinctrl_bmcperiph3: pinctrl@11c42000 {
				compatible = "starfive,jhb100-sys-pinctrl-bmcperiph3";
				reg = <0x0 0x11c42000 0x0 0x1000>;
				resets = <&per3crg JHB100_PER3RST_IOMUX_PRESETN>;
				interrupts = <64>;
				interrupt-controller;
				#interrupt-cells = <2>;
				gpio-controller;
				#gpio-cells = <2>;
				gpio-ranges = <&pinctrl_bmcperiph3 0 0 11>;
			};

			peci0: peci-controller@11c60000 {
				compatible = "starfive,jhb100-peci";
				reg = <0x0 0x11c60000 0x0 0x400>;
				interrupts = <222>;
				clocks = <&per3crg JHB100_PER3CLK_MAIN_ICG_EN_PECI0>;
				resets = <&per3crg JHB100_PER3RST_MAIN_RSTN_PECI0>;
				cmd-timeout-ms = <1000>;
				status = "disabled";
			};

			peci1: peci-controller@11c60400 {
				compatible = "starfive,jhb100-peci";
				reg = <0x0 0x11c60400 0x0 0x400>;
				interrupts = <223>;
				clocks = <&per3crg JHB100_PER3CLK_MAIN_ICG_EN_PECI1>;
				resets = <&per3crg JHB100_PER3RST_MAIN_RSTN_PECI1>;
				cmd-timeout-ms = <1000>;
				status = "disabled";
			};

			hwspinlock: hwspinlock@13012000 {
				compatible = "starfive,jhb100-hwspinlock";
				reg = <0x0 0x13012000 0x0 0x2000>;
				resets = <&sys0crg JHB100_SYS0RST_RESOURCE_ARB>;
				#hwlock-cells = <1>;
				status = "disabled";
			};

			strap_reg: syscon@1301a000 {
				compatible = "starfive,jhb100-strap-syscon", "syscon";
				reg = <0x0 0x1301a000 0x0 0x2000>;
			};

			pvt_sys: pvt@13020000 {
				compatible = "starfive,jhb100-pvt";
				reg = <0x0 0x13020000 0x0 0x80>,
				      <0x0 0x13020080 0x0 0x80>,
				      <0x0 0x13020100 0x0 0x80>;
				reg-names = "common", "ts", "pd";
				clocks = <&sys1crg JHB100_SYS1CLK_APB_SENSOR_ICG_BUF>;
				resets = <&sys1crg JHB100_SYS1RST_MAIN_RSTN_CHIPTOP_SENSOR>;
				interrupts = <53>;
				label = "pvt_sys";
				moortec,ts-coeff-g = <61400>;
				moortec,ts-coeff-h = <253700>;
				#thermal-sensor-cells = <1>;
				status = "disabled";
			};

			pinctrl_sys0: pinctrl@13080000 {
				compatible = "starfive,jhb100-sys-pinctrl-systop-sys0";
				reg = <0x0 0x13080000 0x0 0x800>;
				resets = <&sys0crg JHB100_SYS0RST_SYS0_IOMUX_PRESETN>;
				interrupts = <56>;
				interrupt-controller;
				#interrupt-cells = <2>;
				gpio-controller;
				#gpio-cells = <2>;
				gpio-ranges = <&pinctrl_sys0 0 0 4>;
			};

			pinctrl_sys0h: pinctrl@13080800 {
				compatible = "starfive,jhb100-sys-pinctrl-systop-sys0h";
				reg = <0x0 0x13080800 0x0 0x800>;
				resets = <&sys0crg JHB100_SYS0RST_SYS0H_IOMUX_PRESETN>;
				interrupts = <57>;
				interrupt-controller;
				#interrupt-cells = <2>;
				gpio-controller;
				#gpio-cells = <2>;
				gpio-ranges = <&pinctrl_sys0h 0 0 12>;
			};

			pinctrl_sys1: pinctrl@13081000 {
				compatible = "starfive,jhb100-sys-pinctrl-systop-sys1";
				reg = <0x0 0x13081000 0x0 0x1000>;
				resets = <&sys1crg JHB100_SYS1RST_SYS1_IOMUX_PRESETN>;
				interrupts = <58>;
				interrupt-controller;
				#interrupt-cells = <2>;
				gpio-controller;
				#gpio-cells = <2>;
				gpio-ranges = <&pinctrl_sys1 0 0 8>;
			};

			pinctrl_sys2: pinctrl@13082000 {
				compatible = "starfive,jhb100-sys-pinctrl-systop-sys2";
				reg = <0x0 0x13082000 0x0 0x1000>;
				interrupts = <59>;
				interrupt-controller;
				#interrupt-cells = <2>;
				gpio-controller;
				#gpio-cells = <2>;
				gpio-ranges = <&pinctrl_sys2 0 0 37>;
			};

			jtag1: jtag-master@130c0000 {
				compatible = "starfive,jhb100-jtag";
				reg = <0x0 0x130c0000 0x0 0x100>,
				      <0x0 0x130c0400 0x0 0x400>;
				clocks = <&sys2crg JHB100_SYS2CLK_MAIN_ICG_EN_JTAG1>,
					 <&sys2crg JHB100_SYS2CLK_JTAGM1_200>,
					 <&sys2crg JHB100_SYS2CLK_JTAGM1_100>;
				clock-names = "main", "jtag", "apb";
				resets = <&sys2crg JHB100_SYS2RST_JTAG1_MST_WRAP_HRESETN>,
					<&sys2crg JHB100_SYS2RST_JTAG1_MST_WRAP_APB_PRESETN>;
				status = "disabled";
			};

			jtag0: jtag-master@130c0800 {
				compatible = "starfive,jhb100-jtag";
				reg = <0x0 0x130c0800 0x0 0x100>,
				      <0x0 0x130c0c00 0x0 0x400>;
				clocks = <&sys2crg JHB100_SYS2CLK_MAIN_ICG_EN_JTAG0>,
					 <&sys2crg JHB100_SYS2CLK_JTAGM0_200>,
					 <&sys2crg JHB100_SYS2CLK_JTAGM0_100>;
				clock-names = "main", "jtag", "apb";
				resets = <&sys2crg JHB100_SYS2RST_JTAG0_MST_WRAP_HRESETN>,
					<&sys2crg JHB100_SYS2RST_JTAG0_MST_WRAP_APB_PRESETN>;
				status = "disabled";
			};

			reri0: reri0@130e0000 {
				compatible = "starfive,reri-edac";
				reg = <0x0 0x130e0000 0x0 0x1000>;
				interrupts-extended = <&plic 79>, <&intc 0>;
				interrupt-names = "hp", "lp";
				bank-name = "DDRSS";
				bank-desc = "Port 0 Read SRAM ECC",
					    "Port 1 Read SRAM ECC",
					    "Port 2 Read SRAM ECC",
					    "Port 3 Read SRAM ECC";
				status = "disabled";
			};

			reri1: reri1@130e1000 {
				compatible = "starfive,reri-edac";
				reg = <0x0 0x130e1000 0x0 0x1000>;
				interrupts-extended = <&plic 80>, <&intc 1>;
				interrupt-names = "hp", "lp";
				bank-name = "BMCPCIeRP";
				bank-desc = "PCIE AXI mstr write",
					    "PCIE AXI mstr read",
					    "PCIE AXI slv write",
					    "PCIE AXI slv read",
					    "PCIE Phy SRAM",
					    "MCTP SRAM";
				status = "disabled";
			};

			reri2: reri2@130e2000 {
				compatible = "starfive,reri-edac";
				reg = <0x0 0x130e2000 0x0 0x1000>;
				interrupts-extended = <&plic 81>, <&intc 2>;
				interrupt-names = "hp", "lp";
				bank-name = "BMCPeriph1";
				bank-desc = "UFS Phy SRAM";
				status = "disabled";
			};

			reri3: reri3@130e3000 {
				compatible = "starfive,reri-edac";
				reg = <0x0 0x130e3000 0x0 0x1000>;
				interrupts-extended = <&plic 82>, <&intc 3>;
				interrupt-names = "hp", "lp";
				bank-name = "HOSTSS0";
				bank-desc = "PCIE AXI mstr write",
					    "PCIE AXI mstr read",
					    "PCIE AXI slv write",
					    "PCIE AXI slv read",
					    "PCIE Phy SRAM Ecc",
					    "MCTP SRAM ECC";
				status = "disabled";
			};

			reri4: reri4@130e4000 {
				compatible = "starfive,reri-edac";
				reg = <0x0 0x130e4000 0x0 0x1000>;
				interrupts-extended = <&plic 83>, <&intc 4>;
				interrupt-names = "hp", "lp";
				bank-name = "HOSTSS1";
				bank-desc = "PCIE AXI mstr write",
					    "PCIE AXI mstr read",
					    "PCIE AXI slv write",
					    "PCIE AXI slv read",
					    "PCIE Phy SRAM Ecc",
					    "MCTP SRAM ECC";
				status = "disabled";
			};

			pvt_ddr: pvt@13100000 {
				compatible = "starfive,jhb100-pvt";
				reg = <0x0 0x13100000 0x0 0x80>,
				      <0x0 0x13100080 0x0 0x80>,
				      <0x0 0x13100100 0x0 0x80>;
				reg-names = "common", "ts", "pd";
				clocks = <&pvt_aon>;
				interrupts = <34>;
				label = "pvt_ddr";
				moortec,ts-coeff-g = <61400>;
				moortec,ts-coeff-h = <253700>;
				#thermal-sensor-cells = <1>;
				status = "disabled";
			};

			pvt_cpu: pvt@13210000 {
				compatible = "starfive,jhb100-pvt";
				reg = <0x0 0x13210000 0x0 0x80>,
				      <0x0 0x13210080 0x0 0x80>,
				      <0x0 0x13210100 0x0 0x80>,
				      <0x0 0x13210400 0x0 0x800>;
				reg-names = "common", "ts", "pd", "vm";
				intel,vm-map = [00 ff];
				clocks = <&cpucrg JHB100_CPUCLK_MAIN_ICG_EN_CPUSS_SENSORS>;
				resets = <&cpucrg JHB100_CPURST_MAIN_RSTN_CPUSS_SENSORS>;
				interrupts = <14>;
				label = "pvt_cpu";
				moortec,vm-active-channels = <16>;
				moortec,vm-pre-scaler-x2 = <1 1 1 1 2 1 1 1 1 1 1 1 3 1 1 1>;
				moortec,ts-coeff-g = <61400>;
				moortec,ts-coeff-h = <253700>;
				#thermal-sensor-cells = <1>;
				status = "disabled";
			};

			led0: led@13215000 {
				compatible = "starfive,jhb100-leds";
				reg = <0x0 0x13215000 0x0 0xc>;
				clocks = <&cpucrg JHB100_CPUCLK_MAIN_ICG_EN_CPUSS_HEARTBEAT>;
				resets = <&cpucrg JHB100_CPURST_MAIN_RSTN_HEARTBEAT>;
				status = "disabled";
			};

			l3_pmu: pmu@13216000 {
				compatible = "starfive,jhb100-starnoc-pmu", "starfive,jh8100-starnoc-pmu";
				reg = <0x0 0x13216000 0x0 0x1000>;
				interrupts = <11>, <10>, <12>;
				interrupt-names = "pmu", "llc_irq", "ecc_irq";
			};

			intc: interrupt-controller@13220000 {
				compatible = "starfive,jhb100-intc";
				reg = <0x0 0x13220000 0x0 0x80>;
				interrupts = <1>;
				interrupt-controller;
				#interrupt-cells = <1>;
			};

			ldo0: ldo0@140c0000 {
				compatible = "actt,ldo-regulator";
				reg = <0x0 0x140c0000 0x0 0x80>;
				regulator-min-microvolt = <1000000>;
				regulator-max-microvolt = <1200000>;
				regulator-min-microamp = <366400>;
				regulator-max-microamp = <469300>;
				regulator-initial-microvolt = <1000000>;
				regulator-initial-microamp = <396300>;
				regulator-name = "ldo0";
				clocks = <&per0crg JHB100_PER0CLK_MAIN_ICG_EN_LDO0>;
				resets = <&per0crg JHB100_PER0RST_MAIN_RSTN_LDO0>;
				reset-names = "ldo";
				interrupts = <219>;
				status = "disabled";
			};

			ldo1: ldo1@140c0080 {
				compatible = "actt,ldo-regulator";
				reg = <0x0 0x140c0080 0x0 0x80>;
				regulator-min-microvolt = <1000000>;
				regulator-max-microvolt = <1200000>;
				regulator-min-microamp = <366400>;
				regulator-max-microamp = <469300>;
				regulator-initial-microvolt = <1000000>;
				regulator-initial-microamp = <396300>;
				regulator-name = "ldo1";
				clocks = <&per0crg JHB100_PER0CLK_MAIN_ICG_EN_LDO1>;
				resets = <&per0crg JHB100_PER0RST_MAIN_RSTN_LDO1>;
				reset-names = "ldo";
				interrupts = <220>;
				status = "disabled";
			};

			ddrc_edac: memory-controller@16000000 {
				compatible = "starfive,jhb100-ddrc";
				reg = <0x0 0x16000000 0x0 0x100000>;
				interrupts = <70>;
				starfive,data-width = <16>;
				status = "disabled";
			};

			sfc1: spi@17f00000  {
				compatible = "starfive,jhb100-sfc";
				reg = <0x0 0x17f00000 0x0 0x10000>;
				#address-cells = <1>;
				#size-cells = <0>;
				interrupts = <112>;
				clocks = <&per1crg JHB100_PER1CLK_MAIN_ICG_EN_SFC1>;
				resets = <&per1crg JHB100_PER1RST_MAIN_RSTN_SFC1>;
				reset-names = "spi";
				num-cs = <3>;
				dmas = <&dma_sfc1 0 1 0>;
				dma-names = "rx-tx";
				status = "disabled";
			};

			sfc2: spi@17f10000  {
				compatible = "starfive,jhb100-sfc";
				reg = <0x0 0x17f10000 0x0 0x10000>;
				#address-cells = <1>;
				#size-cells = <0>;
				interrupts = <113>;
				clocks = <&per1crg JHB100_PER1CLK_MAIN_ICG_EN_SFC2>;
				resets = <&per1crg JHB100_PER1RST_MAIN_RSTN_SFC2>;
				reset-names = "spi";
				num-cs = <3>;
				dmas = <&dma_sfc2 0 1 0>;
				dma-names = "rx-tx";
				status = "disabled";
			};

			spi0: spi@17f20000 {
				compatible = "starfive,jhb100-spi";
				reg = <0x0 0x17f20000 0x0 0x10000>;
				#address-cells = <1>;
				#size-cells = <0>;
				interrupts = <110>;
				clocks = <&per1crg JHB100_PER1CLK_MAIN_ICG_EN_SPI0>;
				resets = <&per1crg JHB100_PER1RST_MAIN_RSTN_SPI0>;
				reset-names = "spi";
				num-cs = <2>;
				dmas = <&dma_spi0 0>, <&dma_spi0 1>;
				dma-names = "tx", "rx";
				starfive,syscon = <&per1_syscon>;
				frf = <0>;
				status = "disabled";
			};

			sfc0: spi@18000000 {
				compatible = "starfive,jhb100-sfc";
				reg = <0x0 0x18000000 0x0 0x8000000>;
				#address-cells = <1>;
				#size-cells = <0>;
				interrupts = <111>;
				clocks = <&per1crg JHB100_PER1CLK_MAIN_ICG_EN_SFC0>;
				resets = <&per1crg JHB100_PER1RST_MAIN_RSTN_SFC0>;
				reset-names = "spi";
				num-cs = <2>;
				dmas = <&dma_sfc0 0 1 0>;
				dma-names = "rx-tx";
				status = "disabled";
			};

			dc0_clk: dc0@dc8000 {
				compatible = "verisilicon,dc8000-clk";
				reg = <0x0 0x11135000 0x0 0x200>,
					<0x0 0x11135400 0x0 0x100>;
				interrupts-extended = <&plic 237>, <&intc 53>, <&intc 54>, <&intc 57>;
				interrupt-names = "h2b", "perst_pe", "perst_ne", "espi_rst";
				clocks = <&voutcrg JHB100_VOUTCLK_MAIN_ICG_EN_U0_DC8000>,
					<&voutcrg JHB100_VOUTCLK_U0_DC8000_PIXELCLK0>,
					<&syspll JHB100_SYSPLL_PLL4_OUT>;
				clock-names = "main_icg", "pix_clk", "vout_pix";
				resets = <&voutcrg JHB100_VOUTRST_MAIN_RSTN_U0_DC8000>;
				dc-syscon = <&dcsyscon>;
				starfive,syscon = <&sys_syscon 48 4>;
				memory-region = <&pcie0_media_mem_uncache>;
				host-type = <0>;
				status = "disabled";
			};

			dc1_clk: dc1@dc8000 {
				compatible = "verisilicon,dc8000-clk";
				reg = <0x0 0x11135200 0x0 0x200>,
					<0x0 0x11135500 0x0 0x100>;
				interrupts-extended = <&plic 238>, <&intc 55>, <&intc 56>, <&intc 58>;
				interrupt-names = "h2b", "perst_pe", "perst_ne", "espi_rst";
				clocks = <&voutcrg JHB100_VOUTCLK_MAIN_ICG_EN_U1_DC8000>,
					<&voutcrg JHB100_VOUTCLK_U1_DC8000_PIXELCLK0>,
					<&syspll JHB100_SYSPLL_PLL5_OUT>;
				clock-names = "main_icg", "pix_clk", "vout_pix";
				resets = <&voutcrg JHB100_VOUTRST_MAIN_RSTN_U1_DC8000>;
				dc-syscon = <&dcsyscon>;
				starfive,syscon = <&sys_syscon 48 5>;
				memory-region = <&pcie1_media_mem_uncache>;
				host-type = <1>;
				status = "disabled";
			};
		};

		bus_ioc: bus_ioc {
			compatible = "simple-bus";
			#address-cells = <2>;
			#size-cells = <2>;
			dma-coherent;
			ranges;

			stmmac_axi_setup0: stmmac-axi-config0 {
				snps,wr_osr_lmt = <7>;
				snps,rd_osr_lmt = <7>;
				snps,blen = <256 128 64 32 16 8 4>;
			};

			stmmac_axi_setup1: stmmac-axi-config1 {
				snps,wr_osr_lmt = <15>;
				snps,rd_osr_lmt = <15>;
				snps,blen = <256 128 64 32 16 8 4>;
			};

			gmac2: ethernet@11b80000 {
				compatible = "starfive,jhb100-dwmac", "snps,dwmac-5.20";
				reg = <0x0 0x11b80000 0x0 0x4000>;
				clocks = <&per2crg JHB100_PER2CLK_ETHER0_RMIIANDRGMII_ACLK_I>,
					<&per2crg JHB100_PER2CLK_ETHER0_RMIIANDRGMII_CSR_I>,
					<&per2crg JHB100_PER2CLK_ETHER0_RMIIANDRGMII_PTP_REF_I>,
					<&per2crg JHB100_PER2CLK_GMAC2_RMII_DIV>,
					<&per2crg JHB100_PER2CLK_MAIN_ICG_EN_GMAC2>;
				clock-names = "stmmaceth", "pclk", "ptp_ref", "tx", "gtx";
				resets = <&per2crg JHB100_PER2RST_MAIN_RSTN_GMAC2>;
				reset-names = "stmmaceth";
				interrupts = <140>;
				interrupt-names = "macirq";
				starfive,syscon = <&syscon_bmcperiph2 0x0 0x8>;
				dma-coherent;
				rx-fifo-depth = <8192>;
				tx-fifo-depth = <8192>;
				snps,multicast-filter-bins = <256>;
				snps,perfect-filter-entries = <8>;
				snps,fixed-burst;
				snps,no-pbl-x8;
				snps,axi-config = <&stmmac_axi_setup1>;
				snps,tso;
				snps,en-tx-lpi-clockgating;
				snps,txpbl = <16>;
				snps,rxpbl = <16>;
				status = "disabled";
			};

			gmac3: ethernet@11b84000 {
				compatible = "starfive,jhb100-dwmac", "snps,dwmac-5.20";
				reg = <0x0 0x11b84000 0x0 0x4000>;
				clocks = <&per2crg JHB100_PER2CLK_ETHER1_SGMII_ACLK_I>,
					<&per2crg JHB100_PER2CLK_ETHER1_SGMII_CSR_I>,
					<&per2crg JHB100_PER2CLK_ETHER1_SGMII_PTP_REF_I>,
					<&per2crg JHB100_PER2CLK_GMAC3_TX_DIV>,
					<&per2crg JHB100_PER2CLK_MAIN_ICG_EN_GMAC3>,
					<&per2crg JHB100_PER2CLK_GMAC3_RX_DIV>;
				clock-names = "stmmaceth", "pclk", "ptp_ref", "tx", "gtx", "rx";
				resets = <&per2crg JHB100_PER2RST_MAIN_RSTN_GMAC3>;
				reset-names = "stmmaceth";
				interrupts = <141>;
				interrupt-names = "macirq";
				dma-coherent;
				rx-fifo-depth = <8192>;
				tx-fifo-depth = <8192>;
				snps,multicast-filter-bins = <256>;
				snps,perfect-filter-entries = <8>;
				snps,fixed-burst;
				snps,no-pbl-x8;
				snps,axi-config = <&stmmac_axi_setup1>;
				snps,tso;
				snps,en-tx-lpi-clockgating;
				snps,txpbl = <16>;
				snps,rxpbl = <16>;
				phy-mode = "sgmii";
				phys = <&sgmii_phy0>;
				phy-names = "serdes";
				status = "disabled";
			};

			sgmii_phy0: phy@11b90000 {
				compatible = "starfive,dwmac-inno-sgmii-phy";
				reg = <0x0 0x11b90000 0x0 0x10000>;
				clocks = <&per2crg JHB100_PER2CLK_ETHER1_SGMII_PHY_PCLK_I>,
					 <&per2crg JHB100_PER2CLK_ETHER1_SGMII_REF_25_I>;
				clock-names = "pclk", "ref_25m";
				starfive,syscon = <&syscon_bmcperiph2 0x2a>;
				#phy-cells = <0>;
				status = "disabled";
			};

			dma_system: dma-controller@11bc3000 {
				compatible = "starfive,jhb100-axi-dma-system";
				reg = <0x0 0x11bc3000 0x0 0x1000>;
				clocks = <&per2crg JHB100_PER2CLK_MAIN_ICG_EN_DMAC_1CH>;
				resets = <&per2crg JHB100_PER2RST_MAIN_RSTN_DMAC_8CH>;
				interrupts = <127>;
				#dma-cells = <1>;
				dma-channels = <8>;
				snps,dma-masters = <1>;
				snps,data-width = <3>;
				snps,block-size = <65536 65536 65536 65536 65536
						65536 65536 65536>;
				snps,priority = <0 1 2 3 4 5 6 7>;
				snps,axi-max-burst-len = <16>;
				status = "disabled";
			};

			gmac0: ethernet@11c00000 {
				compatible = "starfive,jhb100-dwmac", "snps,dwmac-5.20";
				reg = <0x0 0x11c00000 0x0 0x4000>;
				clocks = <&per3crg JHB100_PER3CLK_ETHER0_RMII_ACLK_I>,
					<&per3crg JHB100_PER3CLK_ETHER0_RMII_CLK_CSR_I>,
					<&per3crg JHB100_PER3CLK_ETHER0_RMII_CLK_PTP_REF_I>,
					<&per3crg JHB100_PER3CLK_GMAC0_RMII_MUX_DIV2>,
					<&per3crg JHB100_PER3CLK_MAIN_ICG_EN_GMAC0>;
				clock-names = "stmmaceth", "pclk", "ptp_ref", "tx", "gtx";
				resets = <&per3crg JHB100_PER3RST_MAIN_RSTN_GMAC0>;
				reset-names = "stmmaceth";
				interrupts = <224>;
				interrupt-names = "macirq";
				starfive,syscon = <&syscon_bmcperiph3 0x100 0x8>;
				dma-coherent;
				rx-fifo-depth = <8192>;
				tx-fifo-depth = <8192>;
				snps,multicast-filter-bins = <256>;
				snps,perfect-filter-entries = <8>;
				snps,fixed-burst;
				snps,no-pbl-x8;
				snps,axi-config = <&stmmac_axi_setup0>;
				snps,tso;
				snps,txpbl = <16>;
				snps,rxpbl = <16>;
				status = "disabled";
			};

			gmac1: ethernet@11c04000 {
				compatible = "starfive,jhb100-dwmac", "snps,dwmac-5.20";
				reg = <0x0 0x11c04000 0x0 0x4000>;
				clocks = <&per3crg JHB100_PER3CLK_ETHER0_SGMII_ACLK_I>,
					<&per3crg JHB100_PER3CLK_ETHER0_SGMII_CLK_CSR_I>,
					<&per3crg JHB100_PER3CLK_ETHER0_SGMII_CLK_PTP_REF_I>,
					<&per3crg JHB100_PER3CLK_GMAC1_TX>,
					<&per3crg JHB100_PER3CLK_MAIN_ICG_EN_GMAC1>,
					<&per3crg JHB100_PER3CLK_GMAC1_RX>;
				clock-names = "stmmaceth", "pclk", "ptp_ref", "tx", "gtx", "rx";
				resets = <&per3crg JHB100_PER3RST_MAIN_RSTN_GMAC1>;
				reset-names = "stmmaceth";
				interrupts = <225>;
				interrupt-names = "macirq";
				dma-coherent;
				rx-fifo-depth = <8192>;
				tx-fifo-depth = <8192>;
				snps,multicast-filter-bins = <256>;
				snps,perfect-filter-entries = <8>;
				snps,fixed-burst;
				snps,no-pbl-x8;
				snps,axi-config = <&stmmac_axi_setup1>;
				snps,tso;
				snps,en-tx-lpi-clockgating;
				snps,txpbl = <16>;
				snps,rxpbl = <16>;
				phy-mode = "sgmii";
				phys = <&sgmii_phy1>;
				phy-names = "serdes";
				status = "disabled";
			};

			sgmii_phy1: phy@11c10000 {
				compatible = "starfive,dwmac-inno-sgmii-phy";
				reg = <0x0 0x11c10000 0x0 0x10000>;
				clocks = <&per3crg JHB100_PER3CLK_ETHER0_SGMII_PHY_PCLK_I>,
					 <&per3crg JHB100_PER3CLK_ETHER0_SGMII_CLK_REF_25_I>;
				clock-names = "pclk", "ref_25m";
				starfive,syscon = <&syscon_bmcperiph3 0x24>;
				#phy-cells = <0>;
				status = "disabled";
			};
		};

		bus_nioc_4g: bus_nioc_4g {
			compatible = "simple-bus";
			#address-cells = <2>;
			#size-cells = <2>;
			dma-noncoherent;
			ranges;
			dma-ranges = <0x0 0x40000000 0x0 0x40000000 0x1 0x0>,
				     <0x4 0x00000000 0x4 0x00000000 0x1 0x0>;

			emmc0: mmc@11b00000 {
				compatible = "starfive,jhb100-dwcmshc";
				reg = <0x0 0x11b00000 0x0 0x10000>;
				interrupts = <118>;
				clocks = <&per1crg JHB100_PER1CLK_EMMC0_BCLK>,
					 <&per1crg JHB100_PER1CLK_MAIN_ICG_EN_EMMC0>,
					 <&per1crg JHB100_PER1CLK_EMMC0_CCLK>;
				clock-names = "core", "bus", "cclk";
				resets = <&per1crg JHB100_PER1RST_MAIN_RSTN_EMMC0>;
				bus-width = <8>;
				hwlocks = <&hwspinlock 0>;
				supports-cqe;
				status = "disabled";
			};
		};

	};
};
